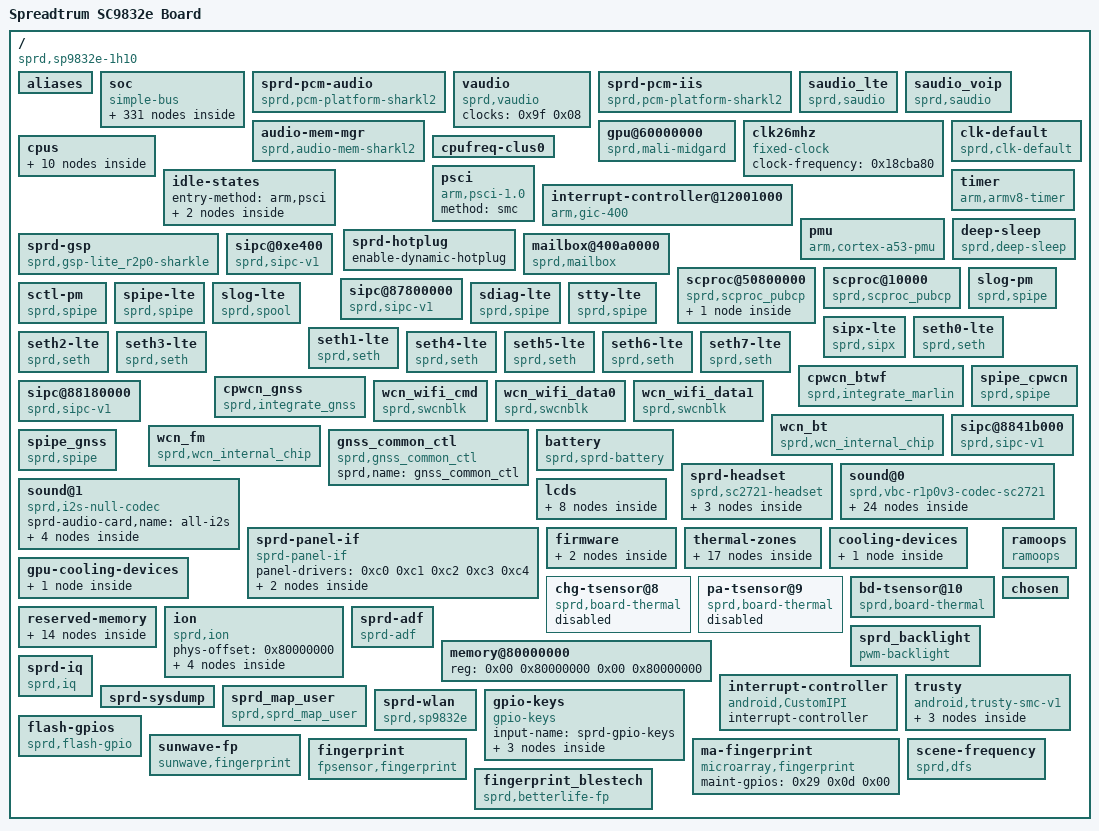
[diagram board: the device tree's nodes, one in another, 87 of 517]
/dts-v1/;

/ {
	interrupt-parent = <0x01>;
	#address-cells = <0x02>;
	#size-cells = <0x02>;
	cpuinfo_hardware = "Spreadtrum SC9832e";
	model = "Spreadtrum SC9832e Board";
	compatible = "sprd,sp9832e-1h10\0sprd,sc9832e";
	sprd,sc-id = <0x2668 0x01 0x20000>;

	aliases {
		serial1 = "/soc/ap-apb/serial@70100000";
		i2c0 = "/soc/ap-apb/i2c@70500000";
		i2c1 = "/soc/ap-apb/i2c@70600000";
		i2c2 = "/soc/ap-apb/i2c@70700000";
		i2c3 = "/soc/ap-apb/i2c@70800000";
		i2c4 = "/soc/ap-apb/i2c@70900000";
		spi0 = "/soc/ap-apb/spi@70a00000";
		spi1 = "/soc/ap-apb/spi@70b00000";
		spi2 = "/soc/ap-apb/spi@70c00000";
		hwspinlock1 = "/soc/aon/hwspinlock@33000000";
		thm-sensor0 = "/soc/aon/gpu-thm@402f0000";
		thm-sensor1 = "/soc/aon/cpu-thm@40300000";
		thm-sensor8 = "/chg-tsensor@8";
		thm-sensor9 = "/pa-tsensor@9";
		thm-sensor10 = "/bd-tsensor@10";
		thm-sensor11 = "/thermal-zones/cpu-thmzone";
		cooling-device0 = "/cooling-devices/cluster0-cooling";
		gpu-cooling0 = "/gpu-cooling-devices/gpu-cooling0";
	};

	soc {
		compatible = "simple-bus";
		#address-cells = <0x02>;
		#size-cells = <0x02>;
		ranges;

		syscon@20e00000 {
			compatible = "sprd,sys-ap-ahb\0syscon";
			reg = <0x00 0x20e00000 0x00 0x10000>;
			hwlocks = <0x02 0x01>;
			hwlock-names = "syscon";
			linux,phandle = <0x21>;
			phandle = <0x21>;
		};

		syscon@300e0000 {
			compatible = "sprd,sys-pub-apb\0syscon";
			reg = <0x00 0x300e0000 0x00 0x10000>;
			linux,phandle = <0xb2>;
			phandle = <0xb2>;
		};

		syscon@40200000 {
			compatible = "sprd,sys-aon-intc\0syscon";
			reg = <0x00 0x40200000 0x00 0x10000>;
			linux,phandle = <0xab>;
			phandle = <0xab>;
		};

		syscon@402b0000 {
			compatible = "sprd,sys-pmu-apb\0syscon";
			reg = <0x00 0x402b0000 0x00 0x10000>;
			#syscon-cells = <0x02>;
			hwlocks = <0x02 0x01>;
			hwlock-names = "syscon";
			linux,phandle = <0x3c>;
			phandle = <0x3c>;
		};

		syscon@402e0000 {
			compatible = "sprd,sys-aon-apb\0syscon";
			reg = <0x00 0x402e0000 0x00 0x10000>;
			hwlocks = <0x02 0x01>;
			hwlock-names = "syscon";
			linux,phandle = <0x2e>;
			phandle = <0x2e>;
		};

		syscon@403c0000 {
			compatible = "sprd,anlg_phy_g1\0syscon";
			reg = <0x00 0x403c0000 0x00 0x10000>;
			hwlocks = <0x02 0x01>;
			hwlock-names = "syscon";
		};

		syscon@403d0000 {
			compatible = "sprd,anlg_phy_g2\0syscon";
			reg = <0x00 0x403d0000 0x00 0x10000>;
			hwlocks = <0x02 0x01>;
			hwlock-names = "syscon";
		};

		syscon@403e0000 {
			compatible = "sprd,anlg_phy_top\0syscon";
			reg = <0x00 0x403e0000 0x00 0x10000>;
			hwlocks = <0x02 0x01>;
			hwlock-names = "syscon";
			linux,phandle = <0x2f>;
			phandle = <0x2f>;
		};

		syscon@403f0000 {
			compatible = "sprd,anlg_phy_g4\0syscon";
			reg = <0x00 0x403f0000 0x00 0x10000>;
			hwlocks = <0x02 0x01>;
			hwlock-names = "syscon";
		};

		syscon@40410000 {
			compatible = "sprd,anlg_phy_g6\0syscon";
			reg = <0x00 0x40410000 0x00 0x10000>;
			hwlocks = <0x02 0x01>;
			hwlock-names = "syscon";
			linux,phandle = <0x3b>;
			phandle = <0x3b>;
		};

		syscon@40420000 {
			compatible = "sprd,anlg_phy_g7\0syscon";
			reg = <0x00 0x40420000 0x00 0x10000>;
			hwlocks = <0x02 0x01>;
			hwlock-names = "syscon";
			linux,phandle = <0x4f>;
			phandle = <0x4f>;
		};

		syscon@40430000 {
			compatible = "sprd,anlg_phy_g8\0syscon";
			reg = <0x00 0x40430000 0x00 0x10000>;
			hwlocks = <0x02 0x01>;
			hwlock-names = "syscon";
		};

		syscon@40440000 {
			compatible = "sprd,anlg_wrap_wcn\0syscon";
			reg = <0x00 0x40440000 0x00 0x10000>;
			hwlocks = <0x02 0x01>;
			hwlock-names = "syscon";
			linux,phandle = <0xb3>;
			phandle = <0xb3>;
		};

		syscon@60d00000 {
			compatible = "sprd,sys-mm-ahb\0syscon";
			reg = <0x00 0x60d00000 0x00 0x10000>;
			hwlocks = <0x02 0x01>;
			hwlock-names = "syscon";
			linux,phandle = <0x4e>;
			phandle = <0x4e>;
		};

		syscon@71300000 {
			compatible = "sprd,sys-ap-apb\0syscon";
			reg = <0x00 0x71300000 0x00 0x40000>;
			hwlocks = <0x02 0x01>;
			hwlock-names = "syscon";
			linux,phandle = <0x20>;
			phandle = <0x20>;
		};

		syscon@71400000 {
			compatible = "sprd,sys-ap-intc\0syscon";
			reg = <0x00 0x71400000 0x00 0x10000>;
			linux,phandle = <0xa7>;
			phandle = <0xa7>;
		};

		syscon@71500000 {
			compatible = "sprd,sys-ap-intc\0syscon";
			reg = <0x00 0x71500000 0x00 0x10000>;
			linux,phandle = <0xa8>;
			phandle = <0xa8>;
		};

		syscon@71600000 {
			compatible = "sprd,sys-ap-intc\0syscon";
			reg = <0x00 0x71600000 0x00 0x10000>;
			linux,phandle = <0xa9>;
			phandle = <0xa9>;
		};

		syscon@71700000 {
			compatible = "sprd,sys-ap-intc\0syscon";
			reg = <0x00 0x71700000 0x00 0x10000>;
			linux,phandle = <0xaa>;
			phandle = <0xaa>;
		};

		ap-apb {
			compatible = "simple-bus";
			#address-cells = <0x02>;
			#size-cells = <0x02>;
			ranges;

			serial@70100000 {
				compatible = "sprd,sc9836-uart";
				reg = <0x00 0x70100000 0x00 0x100>;
				interrupts = <0x00 0x03 0x04>;
				clock-names = "enable\0uart\0source";
				clocks = <0x03 0x0e 0x04 0x05>;
				status = "okay";
			};

			i2c@70500000 {
				compatible = "sprd,r8p0-i2c";
				reg = <0x00 0x70500000 0x00 0x1000>;
				interrupts = <0x00 0x0b 0x04>;
				clock-names = "enable\0i2c\0source";
				clocks = <0x03 0x08 0x06 0x05>;
				clock-frequency = <0x61a80>;
				#address-cells = <0x01>;
				#size-cells = <0x00>;
				status = "okay";

				sensor-main@20 {
					compatible = "sprd,sensor-main";
					reg = <0x20>;
					clock-names = "clk_src\0sensor_eb\0clk_96m\0clk_76m8\0clk_48m\0clk_26m";
					clocks = <0x07 0x08 0x01 0x09 0x0a 0x0b 0x05>;
					vddio-supply = <0x0c>;
					vddcama-supply = <0x0d>;
					vddcamd-supply = <0x0e>;
					vddcammot-supply = <0x0f>;
					reset-gpios = <0x10 0x2c 0x00>;
					power-down-gpios = <0x10 0x2e 0x00>;
					host = "dcam0";

					port {

						endpoint {
							remote-endpoint = <0x11>;
							linux,phandle = <0x63>;
							phandle = <0x63>;
						};
					};
				};

				sensor-main2@6C {
					compatible = "sprd,sensor-main2";
					reg = <0x6c>;
					clock-names = "clk_src\0sensor_eb\0clk_96m\0clk_76m8\0clk_48m\0clk_26m";
					clocks = <0x12 0x08 0x02 0x09 0x0a 0x0b 0x05>;
					vddio-supply = <0x0c>;
					vddcama-supply = <0x0d>;
					vddcamd-supply = <0x0e>;
					vddcammot-supply = <0x0f>;
					reset-gpios = <0x10 0x2d 0x00>;
					power-down-gpios = <0x10 0x2f 0x00>;
					host = "dcam1";

					port {

						endpoint {
							remote-endpoint = <0x13>;
							linux,phandle = <0x65>;
							phandle = <0x65>;
						};
					};
				};
			};

			i2c@70600000 {
				compatible = "sprd,r8p0-i2c";
				reg = <0x00 0x70600000 0x00 0x1000>;
				interrupts = <0x00 0x0c 0x04>;
				clock-names = "enable\0i2c\0source";
				clocks = <0x03 0x09 0x14 0x05>;
				clock-frequency = <0x61a80>;
				#address-cells = <0x01>;
				#size-cells = <0x00>;
				status = "okay";

				sensor-sub@20 {
					compatible = "sprd,sensor-sub";
					reg = <0x20>;
					clock-names = "clk_src\0sensor_eb\0clk_96m\0clk_76m8\0clk_48m\0clk_26m";
					clocks = <0x12 0x08 0x02 0x09 0x0a 0x0b 0x05>;
					vddio-supply = <0x0c>;
					vddcama-supply = <0x0d>;
					vddcamd-supply = <0x0e>;
					vddcammot-supply = <0x0f>;
					reset-gpios = <0x10 0x29 0x00>;
					power-down-gpios = <0x10 0x28 0x00>;
					host = "dcam1";

					port {

						endpoint {
							remote-endpoint = <0x15>;
							linux,phandle = <0x66>;
							phandle = <0x66>;
						};
					};
				};
			};

			i2c@70700000 {
				compatible = "sprd,r8p0-i2c";
				reg = <0x00 0x70700000 0x00 0x1000>;
				interrupts = <0x00 0x0d 0x04>;
				clock-names = "enable\0i2c\0source";
				clocks = <0x03 0x0a 0x16 0x05>;
				clock-frequency = <0x61a80>;
				#address-cells = <0x01>;
				#size-cells = <0x00>;
				status = "okay";
			};

			i2c@70800000 {
				compatible = "sprd,r8p0-i2c";
				reg = <0x00 0x70800000 0x00 0x1000>;
				interrupts = <0x00 0x0e 0x04>;
				clock-names = "enable\0i2c\0source";
				clocks = <0x03 0x0b 0x17 0x05>;
				clock-frequency = <0x61a80>;
				#address-cells = <0x01>;
				#size-cells = <0x00>;
				status = "okay";

				tlsc6x@2e {
					compatible = "tlsc6x,tlsc6x_ts";
					reg = <0x2e>;
					gpios = <0x10 0x91 0x00 0x10 0x90 0x00>;
					vdd_name = "vdd18";
					TP_MAX_X = <480>;
					TP_MAX_Y = <960>;
				};
			};

			i2c@70900000 {
				compatible = "sprd,r8p0-i2c";
				reg = <0x00 0x70900000 0x00 0x1000>;
				interrupts = <0x00 0x0f 0x04>;
				clock-names = "enable\0i2c\0source";
				clocks = <0x03 0x0c 0x18 0x05>;
				clock-frequency = <0x61a80>;
				#address-cells = <0x01>;
				#size-cells = <0x00>;
				status = "okay";

				flash-ic@63 {
					compatible = "sprd,flash-ocp8137";
					reg = <0x63>;
					sprd,flash-ic = <0x1fc9>;
					sprd,torch = <0x01>;
					sprd,preflash = <0x01>;
					sprd,highlight = <0x01>;
					sprd,torch-level = <0x80>;
					sprd,preflash-level = <0x80>;
					sprd,highlight-level = <0x80>;
					sprd,lvfm-enable = <0x01>;
					flash-torch-en-gpios = <0x10 0x58 0x00>;
					flash-chip-en-gpios = <0x10 0x59 0x00>;
					flash-en-gpios = <0x10 0x4c 0x00>;
					flash-sync-gpios = <0x10 0x8d 0x00>;
				};

				charger@6a {
					compatible = "fairchild,fan54015_chg";
					reg = <0x6a>;
					chg-fault-gpios = <0x10 0x08 0x00>;
					vbus-det-gpios = <0x19 0x00 0x00>;
				};
			};

			spi@70a00000 {
				compatible = "sprd,spi-r4p0";
				reg = <0x00 0x70a00000 0x00 0x1000>;
				interrupts = <0x00 0x07 0x04>;
				clock-names = "enable\0spi\0source";
				sprd,dma-mode = <0x00>;
				sprd,rxtx-dma = <0x0b 0x0c>;
				dma-names = "rx_chn\0tx_chn";
				dmas = <0x1a 0x0b 0x1a 0x0c>;
				#address-cells = <0x01>;
				#size-cells = <0x00>;
				status = "okay";
				clocks = <0x03 0x05 0x1b 0x1c>;
			};

			spi@70b00000 {
				compatible = "sprd,spi-r4p0";
				reg = <0x00 0x70b00000 0x00 0x1000>;
				interrupts = <0x00 0x08 0x04>;
				clock-names = "enable\0spi\0source";
				sprd,dma-mode = <0x00>;
				sprd,rxtx-dma = <0x0d 0x0e>;
				dma-names = "rx_chn\0tx_chn";
				dmas = <0x1a 0x0d 0x1a 0x0e>;
				#address-cells = <0x01>;
				#size-cells = <0x00>;
				status = "disabled";
				clocks = <0x1d 0x09 0x1e 0x1c>;
			};

			spi@70c00000 {
				compatible = "sprd,spi-r4p0";
				reg = <0x00 0x70c00000 0x00 0x1000>;
				interrupts = <0x00 0x09 0x04>;
				clock-names = "enable\0spi\0source";
				sprd,dma-mode = <0x00>;
				sprd,rxtx-dma = <0x0f 0x10>;
				dma-names = "rx_chn\0tx_chn";
				dmas = <0x1a 0x0f 0x1a 0x10>;
				#address-cells = <0x01>;
				#size-cells = <0x00>;
				status = "disabled";
				clocks = <0x03 0x07 0x1f 0x1c>;
			};

			i2s@70d00000 {
				compatible = "sprd,i2s";
				reg = <0x00 0x70d00000 0x00 0x100000>;
				sprd,dai_name = "i2s_bt_sco0";
				sprd,hw_port = <0x00>;
				sprd,syscon-ap-apb = <0x20>;
				#sound-dai-cells = <0x00>;
				status = "okay";
				sprd,config_type = "pcm";
				sprd,slave_timeout = <0xf11>;
				sprd,_hw_port = <0x00>;
				sprd,fs = <0x1f40>;
				sprd,bus_type = <0x01>;
				sprd,rtx_mode = <0x03>;
				sprd,byte_per_chan = <0x01>;
				sprd,slave_mode = <0x00>;
				sprd,lsb = <0x00>;
				sprd,lrck = <0x00>;
				sprd,low_for_left = <0x01>;
				sprd,clk_inv = <0x00>;
				sprd,pcm_short_frame = <0x01>;
				sprd,pcm_slot = <0x01>;
				sprd,pcm_cycle = <0x01>;
				sprd,tx_watermark = <0x0c>;
				sprd,rx_watermark = <0x14>;
				linux,phandle = <0xbf>;
				phandle = <0xbf>;
			};
		};

		ap-ahb {
			compatible = "simple-bus";
			#address-cells = <0x02>;
			#size-cells = <0x02>;
			ranges;

			dma-controller@20100000 {
				compatible = "sprd,ap-dma-v4.0";
				reg = <0x00 0x20100000 0x00 0x4000>;
				interrupts = <0x00 0x32 0x04>;
				#dma-cells = <0x01>;
				#dma-channels = <0x1c>;
				sprd,full-type-offset = <0x00>;
				sprd,syscon-dma-glb = <0x21>;
				clock-names = "enable";
				clocks = <0x22 0x05>;
				linux,phandle = <0x1a>;
				phandle = <0x1a>;
			};

			sdio@20600000 {
				compatible = "sprd,sdhc-r10";
				reg = <0x00 0x20600000 0x00 0x1000>;
				interrupts = <0x00 0x3c 0x04>;
				status = "okay";
				clock-names = "sdio_clk\0sdio_clk_source\0sdio_ahb_enable";
				clocks = <0x23 0x24 0x22 0x0b>;
				sprd,hs400es-dly = <0x5a 0x7f 0x30 0x30>;
				sprd,hs400-dly = <0x5a 0x8c 0x30 0x30>;
				sprd,hs200-dly = <0x7f 0x8c 0x8e 0x8e>;
				sprd,ddr52-dly = <0x9f 0xb3 0x1e 0x1e>;
				vmmc-supply = <0x25>;
				voltage-ranges = <0xbb8 0xbb8>;
				bus-width = <0x08>;
				non-removable;
				cap-mmc-hw-reset;
				mmc-hs400-enhanced-strobe;
				mmc-hs400-1_8v;
				mmc-hs200-1_8v;
				mmc-ddr-1_8v;
				sprd,name = "sdio_emmc";
				sprd,sdio-adma;
				no-sdio;
				no-sd;
			};

			sdio@20300000 {
				compatible = "sprd,sdhc-r10";
				reg = <0x00 0x20300000 0x00 0x1000>;
				interrupts = <0x00 0x39 0x04>;
				status = "okay";
				clock-names = "sdio_clk\0sdio_clk_source\0sdio_ahb_enable";
				clocks = <0x26 0x24 0x22 0x08>;
				sprd,sdr104-dly = <0x7f 0x94 0xa7 0xa7>;
				sprd,sdr50-dly = <0x7f 0x4a 0x4a 0x4a>;
				vmmc-supply = <0x27>;
				vqmmc-supply = <0x28>;
				voltage-ranges = <0xbb8 0xbb8>;
				bus-width = <0x04>;
				sd-uhs-sdr50;
				sd-uhs-sdr104;
				cd-gpios = <0x29 0x09 0x00>;
				sprd,name = "sdio_sd";
				sprd,sdio-adma;
				no-sdio;
				no-mmc;
			};

			usb@20200000 {
				compatible = "sprd,usb";
				reg = <0x00 0x20200000 0x00 0x2000>;
				interrupts = <0x00 0x37 0x04>;
				interrupt-names = "mc";
				clocks = <0x22 0x04>;
				clock-names = "core_clk";
				phy-type = "usb20_sprd_phy";
				usb-phy = <0x2a>;
				phy-names = "usb";
				dr-mode = "peripheral";
				sprd,cable-detection-method = "typec";
				sprd,vbus-gpios = <0x19 0x00 0x00>;
			};

			iommu@20800160 {
				compatible = "sprd,iommuexle-dispc";
				reg = <0x00 0x20800160 0x00 0x04 0x00 0x20800800 0x00 0x60 0x00 0x70000000 0x00 0x8000000>;
				reg_name = "mmu_interrupt_reg\0mmu_reg\0iova pool";
				status = "okay";
				#iommu-cells = <0x00>;
				linux,phandle = <0x34>;
				phandle = <0x34>;
			};

			iommu@20a00800 {
				compatible = "sprd,iommuexle-gsp";
				reg = <0x00 0x20a00800 0x00 0x04 0x00 0x20a00804 0x00 0x60 0x00 0x20000000 0x00 0x10000000>;
				reg_name = "mmu_interrupt_reg\0mmu_reg\0iova pool";
				status = "okay";
				#iommu-cells = <0x00>;
				linux,phandle = <0x2b>;
				phandle = <0x2b>;
			};

			gsp@20a00000 {
				compatible = "sprd,gsp-core";
				reg = <0x00 0x20a00000 0x00 0x1000>;
				core-id = <0x00>;
				kcfg-num = <0x08>;
				interrupts = <0x00 0x33 0x04>;
				iommus = <0x2b>;
				sprd,sys-ap-ahb = <0x21>;
				clock-names = "clk_gsp\0clk_gsp_parent\0clk_gsp_eb";
				clocks = <0x2c 0x2d 0x22 0x03>;
				linux,phandle = <0xa6>;
				phandle = <0xa6>;
			};

			hsphy@20e00000 {
				compatible = "sprd,usb-phy";
				reg = <0x00 0x20e00000 0x00 0x3030>;
				reg-names = "phy_glb_regs";
				sprd,syscon-enable = <0x2e>;
				sprd,syscon-usb2iso = <0x2f>;
				sprd,tune-value = <0x5af33>;
				sprd,vdd-voltage = <0x325aa0>;
				#phy-cells = <0x00>;
				vdd-supply = <0x30>;
				linux,phandle = <0x2a>;
				phandle = <0x2a>;
			};

			dispc@20800000 {
				compatible = "sprd,display-controller";
				reg = <0x00 0x20800000 0x00 0x1000>;
				dev-id = <0x00>;
				sprd,dpi_clk_div = <0x01>;
				interrupts = <0x00 0x2e 0x04>;
				clock-src = <0x16e36000 0x7a12000>;
				clock-names = "clk_dispc_core_parent\0clk_dispc_dpi_parent\0clk_dispc_core\0clk_dispc_dpi\0clk_dispc_ahb_eb";
				clocks = <0x2d 0x31 0x32 0x33 0x22 0x01>;
				iommus = <0x34>;
				status = "okay";
				sprd,ip = "dpu-lite-r1p0";
				sprd,soc = "sharkle";
				linux,phandle = <0xd3>;
				phandle = <0xd3>;

				port {

					endpoint@0 {
						remote-endpoint = <0x35>;
						linux,phandle = <0x37>;
						phandle = <0x37>;
					};
				};
			};

			dsi@21800000 {
				compatible = "sprd,dsi-controller";
				#address-cells = <0x01>;
				#size-cells = <0x00>;
				dev-id = <0x00>;
				reg = <0x00 0x21800000 0x00 0x1000>;
				interrupts = <0x00 0x30 0x04 0x00 0x31 0x04>;
				clock-names = "clk_dsi0_ahb_eb";
				clocks = <0x22 0x00>;
				status = "okay";
				sprd,ip = "sprd,dsi-ctrl-r1p0";
				sprd,soc = "sharkle";

				port@0 {
					reg = <0x00>;

					endpoint {
						remote-endpoint = <0x36>;
						linux,phandle = <0x39>;
						phandle = <0x39>;
					};
				};

				port@1 {
					reg = <0x01>;

					endpoint {
						remote-endpoint = <0x37>;
						linux,phandle = <0x35>;
						phandle = <0x35>;
					};
				};
			};

			dphy@0 {
				compatible = "sprd,mipi-dsi-phy";
				#address-cells = <0x01>;
				#size-cells = <0x00>;
				reg = <0x00 0x21800000 0x00 0x1000>;
				status = "okay";
				sprd,ip = "sprd,megacores-sharkle";
				sprd,soc = "sharkle";

				port@0 {
					reg = <0x00>;

					endpoint {
						remote-endpoint = <0x38>;
						linux,phandle = <0xc5>;
						phandle = <0xc5>;
					};
				};

				port@1 {
					reg = <0x01>;

					endpoint {
						remote-endpoint = <0x39>;
						linux,phandle = <0x36>;
						phandle = <0x36>;
					};
				};
			};

			lcds {

				lcdffff@0 {
					work-mode = <0x01>;
					bpp = <0x18>;
					lane-number = <0x04>;
					fps = <0x3c>;
					panel-name = "lcd_dummy_mipi_hd";
					power-on-sequence = <0x32 0x01 0x14 0x32 0x00 0x14 0x32 0x01 0x78>;
					power-off-sequence = <0x32 0x00 0x14>;
					init-data = <0x15780002 0x11001500 0x22900>;
					sleep-in = <0x15000002 0x28001578 0x21000>;
					sleep-out = <0x15780002 0x11001500 0x22900>;
					linux,phandle = <0xc4>;
					phandle = <0xc4>;

					display-timings {
						clock-frequency = <0x7a120>;
						hactive = <0x2d0>;
						vactive = <0x500>;
						hback-porch = <0x30>;
						hfront-porch = <0x30>;
						vback-porch = <0x10>;
						vfront-porch = <0x10>;
						hsync-len = <0x08>;
						vsync-len = <0x08>;
					};
				};
			};
		};

		aon {
			compatible = "simple-bus";
			#address-cells = <0x02>;
			#size-cells = <0x02>;
			ranges;

			hwspinlock@33000000 {
				compatible = "sprd,hwspinlock-r3p0";
				reg = <0x00 0x33000000 0x00 0x1000>;
				#hwlock-cells = <0x01>;
				hwlocks-base = <0x00>;
				hwlocks-num = <0x20>;
				clock-names = "enable";
				clocks = <0x3a 0x16>;
				linux,phandle = <0x02>;
				phandle = <0x02>;
			};

			audio-codec@40000000 {
				compatible = "sprd,sharkl2-audio-codec";
				reg = <0x00 0x40000000 0x00 0x2000>;
				interrupts = <0x00 0x14 0x00>;
				sprd,syscon-aon-apb = <0x2e>;
				sprd,anlg-phy-g-syscon = <0x3b>;
				linux,phandle = <0x4d>;
				phandle = <0x4d>;
			};

			vbc@40020000 {
				compatible = "sprd,vbc-r1p0v3";
				#sound-dai-cells = <0x01>;
				reg = <0x00 0x40020000 0x00 0x10000>;
				sprd,clk-stable = <0x402d0060 0x04>;
				sprd,syscon-aon-apb = <0x2e>;
				sprd,syscon-pmu-apb = <0x3c>;
				sprd,dynamic-eq-support = <0x00>;
				sprd,vbc-iis-lr-invert = <0x00 0x01 0x01>;
				sprd,vbc-use-dma-type = <0x00 0x00 0x01 0x01>;
				sprd,vbc-use-ad01-only = <0x01>;
				pinctrl-names = "vbc_iis1_0\0ap_iis0_0\0tgdsp_iis0_0\0tgdsp_iis1_0\0pubcp_iis0_0\0ap_iis0_1\0tgdsp_iis0_1\0tgdsp_iis1_1\0pubcp_iis0_1\0vbc_iis2_1\0vbc_iis3_1";
				pinctrl-0 = <0x3d>;
				pinctrl-1 = <0x3e>;
				pinctrl-2 = <0x3f>;
				pinctrl-3 = <0x40>;
				pinctrl-4 = <0x41>;
				pinctrl-5 = <0x42>;
				pinctrl-6 = <0x43>;
				pinctrl-7 = <0x44>;
				pinctrl-8 = <0x45>;
				pinctrl-9 = <0x46>;
				pinctrl-10 = <0x47>;
				linux,phandle = <0xbb>;
				phandle = <0xbb>;
			};

			timer@40050000 {
				compatible = "sprd,bcevt-r4p0";
				reg = <0x00 0x40050000 0x00 0x14>;
				interrupts = <0x00 0x1c 0x04>;
				clock-frequency = <0x8000>;
			};

			dma-controller@40100000 {
				compatible = "sprd,aon-dma-v2.0";
				reg = <0x00 0x40100000 0x00 0x4000>;
				#dma-cells = <0x01>;
				#dma-channels = <0x08>;
				sprd,full-type-offset = <0x00>;
				sprd,syscon-dma-glb = <0x2e>;
				clock-names = "enable";
				clocks = <0x48 0x16>;
				linux,phandle = <0x9d>;
				phandle = <0x9d>;
			};

			gpio-controller@40210000 {
				compatible = "sprd,ap-eic";
				reg = <0x00 0x40210000 0x00 0x80 0x00 0x40370000 0x00 0x80 0x00 0x402c0000 0x00 0x80>;
				gpio-controller;
				#gpio-cells = <0x02>;
				sprd,gpiobase = <0x120>;
				sprd,ngpios = <0x20>;
				interrupt-controller;
				#interrupt-cells = <0x02>;
				interrupts = <0x00 0x25 0x04>;
				linux,phandle = <0xda>;
				phandle = <0xda>;
			};

			gpio-controller@402100a0 {
				compatible = "sprd,ap-eic-async";
				reg = <0x00 0x402100a0 0x00 0x40 0x00 0x403700a0 0x00 0x40 0x00 0x402c00a0 0x00 0x40>;
				gpio-controller;
				#gpio-cells = <0x02>;
				sprd,gpiobase = <0x150>;
				sprd,ngpios = <0x20>;
				interrupt-controller;
				#interrupt-cells = <0x02>;
				interrupts = <0x00 0x25 0x04>;
				linux,phandle = <0x29>;
				phandle = <0x29>;
			};

			efuse@40240000 {
				compatible = "sprd,ap_r6p0_efuse";
				sprd,syscon-enable = <0x2e>;
				reg = <0x00 0x40240000 0x00 0x10000>;
				clock-names = "enable";
				clocks = <0x3a 0x0d>;
				sprd,uid-start = <0x5e 0x00>;
				sprd,uid-end = <0x5f 0x00>;
				sprd,block-start = <0x24>;
				sprd,block-num = <0x0a>;
				sprd,block-width = <0x20>;
				hwlocks = <0x02 0x08>;
				hwlock-names = "ap_efuse";
			};

			gpio-controller@40280000 {
				compatible = "sprd,ap-gpio";
				reg = <0x00 0x40280000 0x00 0x1000>;
				gpio-controller;
				#gpio-cells = <0x02>;
				sprd,gpiobase = <0x00>;
				sprd,ngpios = <0x100>;
				interrupt-controller;
				#interrupt-cells = <0x02>;
				interrupts = <0x00 0x23 0x04>;
				linux,phandle = <0x10>;
				phandle = <0x10>;
			};

			pinctrl@402a0000 {
				compatible = "sprd,sc9832e-pinctrl";
				reg = <0x00 0x402a0000 0x00 0x10000>;

				reg2-iis0-0 {
					pins = <0x1c11032 0x00>;
					linux,phandle = <0x3d>;
					phandle = <0x3d>;
				};

				reg2-iis0-1 {
					pins = <0x1c11032 0x01>;
					linux,phandle = <0x3e>;
					phandle = <0x3e>;
				};

				reg3-iis0-2 {
					pins = <0x1c11032 0x02>;
					linux,phandle = <0x3f>;
					phandle = <0x3f>;
				};

				reg2-iis0-3 {
					pins = <0x1c11032 0x03>;
					linux,phandle = <0x40>;
					phandle = <0x40>;
				};

				reg2-iis0-4 {
					pins = <0x1c11032 0x04>;
					linux,phandle = <0x41>;
					phandle = <0x41>;
				};

				reg3-iis1-0 {
					pins = <0x2710a33 0x00>;
					linux,phandle = <0x42>;
					phandle = <0x42>;
				};

				reg3-iis1-1 {
					pins = <0x2710a33 0x02>;
					linux,phandle = <0x43>;
					phandle = <0x43>;
				};

				reg3-iis1-2 {
					pins = <0x2710a33 0x03>;
					linux,phandle = <0x44>;
					phandle = <0x44>;
				};

				reg3-iis1-3 {
					pins = <0x2710a33 0x01>;
					linux,phandle = <0x45>;
					phandle = <0x45>;
				};

				reg3-iis1-4 {
					pins = <0x2710a33 0x04>;
					linux,phandle = <0x46>;
					phandle = <0x46>;
				};

				reg3-iis1-5 {
					pins = <0x2710a33 0x05>;
					linux,phandle = <0x47>;
					phandle = <0x47>;
				};
			};

			gpu-thm@402f0000 {
				compatible = "sprd,r2p0-thm";
				sprd,syscon-enable = <0x2e>;
				reg = <0x00 0x402f0000 0x00 0x100>;
				clock-names = "enable";
				clocks = <0x48 0x01>;
				#thermal-sensor-cells = <0x01>;
				power-down = <0x00>;
				otp-temp = <0x1d4c0>;
				algor_ver = <0x01>;
				cal_k = <0x387>;
				cal_b = <0x1167a>;
				cal_efuse_blk = <0x2c>;
				cal_efuse_bit = <0x09>;
				ratio_off_bit = <0x02>;
				ratio_sign_bit = <0x01>;
				linux,phandle = <0xc9>;
				phandle = <0xc9>;
			};

			cpu-thm@40300000 {
				compatible = "sprd,r2p0-thm";
				sprd,syscon-enable = <0x2e>;
				reg = <0x00 0x40300000 0x00 0x100>;
				clock-names = "enable";
				clocks = <0x48 0x13>;
				#thermal-sensor-cells = <0x01>;
				power-down = <0x00>;
				otp-temp = <0x1d4c0>;
				algor_ver = <0x01>;
				cal_k = <0x387>;
				cal_b = <0x1167a>;
				cal_efuse_blk = <0x2c>;
				cal_efuse_bit = <0x18>;
				ratio_off_bit = <0x11>;
				ratio_sign_bit = <0x10>;
				linux,phandle = <0xc6>;
				phandle = <0xc6>;
			};

			pwm@40260020 {
				#pwm-cells = <0x02>;
				compatible = "sprd,pwm-r3p0";
				reg = <0x00 0x40260020 0x00 0x10000>;
				status = "okay";
				clock-names = "sprd_pwm_clk_parent\0clk_pwm";
				clocks = <0x05 0x49>;
				linux,phandle = <0xd4>;
				phandle = <0xd4>;
			};

			watchdog@40310000 {
				compatible = "sprd,sharkl2-wdt";
				reg = <0x00 0x40310000 0x00 0x1000>;
				interrupts = <0x00 0x7c 0x04>;
				clock-names = "enable\0rtc_enable";
				sprd,wdt-enable = <0x2e>;
				sprd,wdt-phandle = <0x4a>;
				clocks = <0x48 0x08 0x4b 0x09>;
			};

			spi@40380000 {
				compatible = "sprd,r3p0-adi";
				reg = <0x00 0x40380000 0x00 0x10000>;
				#address-cells = <0x01>;
				#size-cells = <0x00>;
				sprd,hw-channels = <0x1e 0x8c20>;

				pmic@0 {
					compatible = "sprd,sc2721";
					reg = <0x00>;
					spi-max-frequency = <0x18cba80>;
					#address-cells = <0x01>;
					#size-cells = <0x00>;
					interrupt-controller;
					#interrupt-cells = <0x02>;
					interrupts = <0x00 0x26 0x04>;
					sprd,pmic_intc_base = <0xc0>;
					sprd,pmic_intc_irqmax = <0x10>;
					linux,phandle = <0x4c>;
					phandle = <0x4c>;

					timer@00 {
						compatible = "sprd,sc2721-chg-timer";
						reg = <0x00>;
						interrupt-parent = <0x4c>;
						interrupts = <0x07 0x04>;
					};

					watchdog@40 {
						compatible = "sprd,sc2721-wdt";
						reg = <0x40>;
						linux,phandle = <0x4a>;
						phandle = <0x4a>;
					};

					watchdog@80 {
						compatible = "sprd,sc2721-chg-wdt";
						reg = <0x80>;
						status = "disabled";
					};

					bltc-rgb@180 {
						compatible = "sprd,sc2721-bltc-rgb";
						reg = <0x180>;
						status = "okay";
					};

					rtc@200 {
						compatible = "sprd,sc2721-rtc";
						interrupt-parent = <0x4c>;
						interrupts = <0x01 0x04>;
						reg = <0x200>;
					};

					gpio-controller@280 {
						compatible = "sprd,sc2721-eic";
						reg = <0x280>;
						interrupts = <0x04 0x04>;
						interrupt-parent = <0x4c>;
						gpio-controller;
						#gpio-cells = <0x02>;
						sprd,gpiobase = <0x140>;
						sprd,ngpios = <0x10>;
						interrupt-controller;
						#interrupt-cells = <0x02>;
						linux,phandle = <0x19>;
						phandle = <0x19>;
					};

					kpled@2ac {
						compatible = "sprd,sc2721-kpled";
						brightness_max = <0xff>;
						brightness_min = <0x00>;
						run_mode = <0x01>;
						reg = <0x2ac 0x2b0>;
						status = "disabled";
					};

					flash-kpled {
						compatible = "sprd,flash-kpled";
					};

					flash-sink {
						compatible = "sprd,flash-sink";
					};

					efuse@300 {
						compatible = "sprd,sc2721-efuse";
						reg = <0x300>;
						sprd,block-num = <0x20>;
						sprd,block-width = <0x10>;
						hwlocks = <0x02 0x0c>;
						hwlock-names = "pmic_efuse";
					};

					typec@380 {
						compatible = "sprd,typec";
						interrupt-parent = <0x4c>;
						interrupts = <0x0a 0x04>;
						reg = <0x380>;
						mode = <0x02>;
						tsleep = <0x00>;
						ext-ldo-sw = <0x00>;
						status = "okay";
					};

					adc@400 {
						compatible = "sprd,sc2721-adc";
						reg = <0x400>;
						#io-channel-cells = <0x01>;
						hwlocks = <0x02 0x04>;
						hwlock-names = "pmic_adc";
						linux,phandle = <0xb8>;
						phandle = <0xb8>;
					};

					audio-codec@700 {
						compatible = "sprd,sc2721-audio-codec";
						#sound-dai-cells = <0x01>;
						reg = <0x700>;
						interrupts = <0x06 0x00>;
						sprd,syscon-pmu-apb = <0x3c>;
						status = "okay";
						digital-codec = <0x4d>;
						linux,phandle = <0xbc>;
						phandle = <0xbc>;
					};

					power-controller@810 {
						compatible = "sprd,sc2721-regulator";
						reg = <0xc28 0xcd4 0xd00 0xd1c 0xd20 0xd3c>;

						regulators {
							#address-cells = <0x01>;
							#size-cells = <0x00>;

							dcdc@0 {
								reg = <0x00>;
								regulator-name = "vddcpu";
								sprd,default-microvolt = <0xdbba0>;
								sprd,step-microvolt = <0xc35>;
								regulator-min-microvolt = <0x61a80>;
								regulator-max-microvolt = <0x1e74e0>;
								regulator-microvolt-offset = <0x00>;
								sprd,hide-offset = <0x3e8>;
								sprd,default-on;
								linux,phandle = <0xa4>;
								phandle = <0xa4>;
							};

							dcdc@1 {
								reg = <0x01>;
								regulator-name = "vddcore";
								sprd,default-microvolt = <0xdbba0>;
								sprd,step-microvolt = <0xc35>;
								regulator-min-microvolt = <0x61a80>;
								regulator-max-microvolt = <0x1e74e0>;
								regulator-microvolt-offset = <0x00>;
								sprd,hide-offset = <0x3e8>;
								sprd,default-on;
								linux,phandle = <0xa0>;
								phandle = <0xa0>;
							};

							dcdc@2 {
								reg = <0x02>;
								regulator-name = "vddmem";
								sprd,default-microvolt = <0x155cc0>;
								sprd,step-microvolt = <0xc35>;
								regulator-min-microvolt = <0x61a80>;
								regulator-max-microvolt = <0x1e74e0>;
								regulator-microvolt-offset = <0x00>;
								sprd,hide-offset = <0x3e8>;
								sprd,default-on;
							};

							dcdc@3 {
								reg = <0x03>;
								regulator-name = "vddgen";
								sprd,default-microvolt = <0x1c3a90>;
								sprd,step-microvolt = <0xc35>;
								regulator-min-microvolt = <0x927c0>;
								regulator-max-microvolt = <0x387520>;
								regulator-microvolt-offset = <0x00>;
								sprd,hide-offset = <0x3e8>;
								sprd,default-on;
							};

							dcdc@4 {
								reg = <0x04>;
								regulator-name = "vddwpa";
								sprd,default-microvolt = <0xf4240>;
								sprd,step-microvolt = <0xc35>;
								regulator-min-microvolt = <0x927c0>;
								regulator-max-microvolt = <0x36dee0>;
								regulator-microvolt-offset = <0x00>;
								sprd,hide-offset = <0x3e8>;
							};

							ldo@5 {
								reg = <0x05>;
								regulator-name = "vddcama";
								sprd,default-microvolt = <0x2ab980>;
								sprd,step-microvolt = <0x2710>;
								regulator-min-microvolt = <0x124f80>;
								regulator-max-microvolt = <0x393870>;
								regulator-microvolt-offset = <0x00>;
								sprd,hide-offset = <0x3e8>;
								linux,phandle = <0x0d>;
								phandle = <0x0d>;
							};

							ldo@6 {
								reg = <0x06>;
								regulator-name = "vddcammot";
								sprd,default-microvolt = <0x2ab980>;
								sprd,step-microvolt = <0x2710>;
								regulator-min-microvolt = <0x124f80>;
								regulator-max-microvolt = <0x393870>;
								regulator-microvolt-offset = <0x00>;
								sprd,hide-offset = <0x3e8>;
								linux,phandle = <0x0f>;
								phandle = <0x0f>;
							};

							ldo@7 {
								reg = <0x07>;
								regulator-name = "vddsim0";
								sprd,default-microvolt = <0x1b7740>;
								sprd,step-microvolt = <0x2710>;
								regulator-min-microvolt = <0x124f80>;
								regulator-max-microvolt = <0x23c3460>;
								regulator-microvolt-offset = <0x00>;
								sprd,hide-offset = <0x3e8>;
								status = "disabled";
							};

							ldo@8 {
								reg = <0x08>;
								regulator-name = "vddsim1";
								sprd,default-microvolt = <0x1b7740>;
								sprd,step-microvolt = <0x2710>;
								regulator-min-microvolt = <0x124f80>;
								regulator-max-microvolt = <0x393870>;
								regulator-microvolt-offset = <0x00>;
								sprd,hide-offset = <0x3e8>;
								status = "disabled";
							};

							ldo@9 {
								reg = <0x09>;
								regulator-name = "vddsim2";
								sprd,default-microvolt = <0x1b7740>;
								sprd,step-microvolt = <0x2710>;
								regulator-min-microvolt = <0x124f80>;
								regulator-max-microvolt = <0x393870>;
								regulator-microvolt-offset = <0x00>;
								sprd,hide-offset = <0x3e8>;
							};

							ldo@10 {
								reg = <0x0a>;
								regulator-name = "vddemmccore";
								sprd,default-microvolt = <0x2dc6c0>;
								sprd,step-microvolt = <0x2710>;
								regulator-min-microvolt = <0x124f80>;
								regulator-max-microvolt = <0x393870>;
								regulator-microvolt-offset = <0x00>;
								sprd,default-on;
								sprd,hide-offset = <0x3e8>;
								linux,phandle = <0x25>;
								phandle = <0x25>;
							};

							ldo@11 {
								reg = <0x0b>;
								regulator-name = "vddsdcore";
								sprd,default-microvolt = <0x2dc6c0>;
								sprd,step-microvolt = <0x2710>;
								regulator-min-microvolt = <0x124f80>;
								regulator-max-microvolt = <0x393870>;
								regulator-microvolt-offset = <0x00>;
								sprd,default-on;
								sprd,hide-offset = <0x3e8>;
								regulator-always-on;
								linux,phandle = <0x27>;
								phandle = <0x27>;
							};

							ldo@12 {
								reg = <0x0c>;
								regulator-name = "vddsdio";
								sprd,default-microvolt = <0x2dc6c0>;
								sprd,step-microvolt = <0x2710>;
								regulator-min-microvolt = <0x124f80>;
								regulator-max-microvolt = <0x393870>;
								regulator-microvolt-offset = <0x00>;
								sprd,default-on;
								sprd,hide-offset = <0x3e8>;
								linux,phandle = <0x28>;
								phandle = <0x28>;
							};

							ldo@13 {
								reg = <0x0d>;
								regulator-name = "vdd28";
								sprd,default-microvolt = <0x2ab980>;
								sprd,step-microvolt = <0x2710>;
								regulator-min-microvolt = <0x124f80>;
								regulator-max-microvolt = <0x393870>;
								regulator-microvolt-offset = <0x00>;
								sprd,default-on;
								sprd,hide-offset = <0x3e8>;
							};

							ldo@14 {
								reg = <0x0e>;
								regulator-name = "vddwifipa";
								sprd,default-microvolt = <0x325aa0>;
								sprd,step-microvolt = <0x2710>;
								regulator-min-microvolt = <0x124f80>;
								regulator-max-microvolt = <0x393870>;
								regulator-microvolt-offset = <0x00>;
								sprd,hide-offset = <0x3e8>;
								linux,phandle = <0xb6>;
								phandle = <0xb6>;
							};

							ldo@15 {
								reg = <0x0f>;
								regulator-name = "vdddcxo";
								sprd,default-microvolt = <0x1b7740>;
								sprd,step-microvolt = <0x2710>;
								regulator-min-microvolt = <0x124f80>;
								regulator-max-microvolt = <0x393870>;
								regulator-microvolt-offset = <0x00>;
								sprd,default-on;
								sprd,hide-offset = <0x3e8>;
							};

							ldo@16 {
								reg = <0x10>;
								regulator-name = "vddusb33";
								sprd,default-microvolt = <0x325aa0>;
								sprd,step-microvolt = <0x2710>;
								regulator-min-microvolt = <0x124f80>;
								regulator-max-microvolt = <0x393870>;
								regulator-microvolt-offset = <0x00>;
								sprd,default-on;
								sprd,hide-offset = <0x3e8>;
								linux,phandle = <0x30>;
								phandle = <0x30>;
							};

							ldo@17 {
								reg = <0x11>;
								regulator-name = "vddcamd";
								sprd,default-microvolt = <0x10c8e0>;
								sprd,step-microvolt = <0x186a>;
								regulator-min-microvolt = <0xf4240>;
								regulator-max-microvolt = <0x16e360>;
								regulator-microvolt-offset = <0x00>;
								sprd,hide-offset = <0x3e8>;
								linux,phandle = <0x0e>;
								phandle = <0x0e>;
							};

							ldo@18 {
								reg = <0x12>;
								regulator-name = "vddcon";
								sprd,default-microvolt = <0x186a00>;
								sprd,step-microvolt = <0x186a>;
								regulator-min-microvolt = <0x10c8e0>;
								regulator-max-microvolt = <0x186a00>;
								regulator-microvolt-offset = <0x00>;
								sprd,hide-offset = <0x3e8>;
								linux,phandle = <0xb5>;
								phandle = <0xb5>;
							};

							ldo@19 {
								reg = <0x13>;
								regulator-name = "vddcamio";
								sprd,default-microvolt = <0x1b7740>;
								sprd,step-microvolt = <0x186a>;
								regulator-min-microvolt = <0x10c8e0>;
								regulator-max-microvolt = <0x1cfde0>;
								regulator-microvolt-offset = <0x00>;
								sprd,hide-offset = <0x3e8>;
								sprd,default-on;
								linux,phandle = <0x0c>;
								phandle = <0x0c>;
							};

							ldo@20 {
								reg = <0x14>;
								regulator-name = "vdd18";
								sprd,default-microvolt = <0x1b7740>;
								sprd,step-microvolt = <0x186a>;
								regulator-min-microvolt = <0x10c8e0>;
								regulator-max-microvolt = <0x1cfde0>;
								regulator-microvolt-offset = <0x00>;
								sprd,hide-offset = <0x3e8>;
								sprd,default-on;
							};

							ldo@21 {
								reg = <0x15>;
								regulator-name = "vddrf18";
								sprd,default-microvolt = <0x1b7740>;
								sprd,step-microvolt = <0x186a>;
								regulator-min-microvolt = <0x10c8e0>;
								regulator-max-microvolt = <0x1cfde0>;
								regulator-microvolt-offset = <0x00>;
								sprd,default-on;
								sprd,hide-offset = <0x3e8>;
							};

							ldo@22 {
								reg = <0x16>;
								regulator-name = "vddrf15";
								sprd,default-microvolt = <0x1312d0>;
								sprd,step-microvolt = <0x186a>;
								regulator-min-microvolt = <0x10c8e0>;
								regulator-max-microvolt = <0x155cc0>;
								regulator-microvolt-offset = <0x00>;
								sprd,hide-offset = <0x3e8>;
							};

							ldo@23 {
								reg = <0x17>;
								regulator-name = "vddldomem";
								sprd,default-microvolt = <0x1312d0>;
								sprd,step-microvolt = <0x186a>;
								regulator-min-microvolt = <0x10c8e0>;
								regulator-max-microvolt = <0x155cc0>;
								regulator-microvolt-offset = <0x00>;
								sprd,hide-offset = <0x3e8>;
								sprd,default-on;
							};
						};
					};

					fast-charger@900 {
						compatible = "sprd,sc2721-fchg";
						reg = <0x900>;
						interrupt-parent = <0x4c>;
						interrupts = <0x05 0x04>;
						status = "disabled";
					};

					fgu@a00 {
						compatible = "sprd,sc2721-fgu";
						reg = <0xa00>;
						interrupt-parent = <0x4c>;
						interrupts = <0x03 0x04>;
						ocv-type = <0x01>;
					};

					global@c00 {
						compatible = "sprd,pmic-glb";
						reg = <0xc00>;
					};

					vibrator@eb4 {
						compatible = "sprd,sc2721-vibrator";
						reg = <0xeb4>;
					};

					charger@ec0 {
						compatible = "sprd,sc2721-charger";
						reg = <0xec0>;
						chg-cv-gpios = <0x19 0x04 0x00>;
						chg-ovi-gpios = <0x19 0x06 0x00>;
						status = "okay";
					};

					power@efc {
						compatible = "sprd,sc2721-poweroff";
						reg = <0xefc>;
					};

					reset@f1c {
						compatible = "sprd,sc2721-7sreset";
						reg = <0xf1c 0xeec>;
					};
				};
			};

			aon-bm@40340000 {
				compatible = "sprd,aon-bm-r5p3";
				reg = <0x00 0x40340000 0x00 0x10000>;
				interrupts = <0x00 0x22 0x04>;
				sprd,aon-glb = <0x2e>;
				bm-names = "AP\0WTLCP\0PUBCP\0WCN";
				bm-daps = <0x01 0x02 0x03 0x04>;
				aon_dap_index = <0x03>;
			};

			modem-dbg-log@40470000 {
				compatible = "sprd,dbg-log-sharkle";
				reg = <0x00 0x40470000 0x00 0x1000 0x00 0x403e0000 0x00 0x1000 0x00 0x40420000 0x00 0x1000>;
				sprd,syscon-pmu-apb = <0x3c>;
				sprd,syscon-aon-apb = <0x2e>;
				sprd,syscon-mm-ahb = <0x4e>;
				sprd,syscon-anlg-phy-g7 = <0x4f>;
			};
		};

		mm {
			compatible = "simple-bus";
			#address-cells = <0x02>;
			#size-cells = <0x02>;
			ranges;

			video-codec@21900000 {
				compatible = "sprd,sharkle-vsp";
				reg = <0x00 0x21900000 0x00 0xc000>;
				interrupts = <0x00 0x2b 0x04>;
				sprd,syscon-pmu-apb = <0x3c>;
				sprd,syscon-aon-apb = <0x2e>;
				sprd,syscon-mm-ahb = <0x21>;
				iommus = <0x50>;
				status = "ok";
				clock-names = "clk_ahb_gate_vsp_eb\0clk_vsp";
				clocks = <0x22 0x02 0x51>;
			};

			iommu@21901004 {
				compatible = "sprd,iommuexle-vsp";
				reg = <0x00 0x21901004 0x00 0x04 0x00 0x21901140 0x00 0x60 0x00 0x10000000 0x00 0x10000000>;
				reg_name = "mmu_interrupt_reg\0mmu_reg\0iova pool";
				status = "okay";
				#iommu-cells = <0x00>;
				linux,phandle = <0x50>;
				phandle = <0x50>;
			};

			dcam@60800000 {
				compatible = "sprd,dcam";
				reg = <0x00 0x60800000 0x00 0x1000 0x00 0x60801000 0x00 0x1000 0x00 0x60802000 0x00 0x1000 0x00 0x60803000 0x00 0x1000 0x00 0x60804000 0x00 0x4000 0x00 0x60808000 0x00 0x4000>;
				interrupts = <0x00 0x2d 0x04 0x00 0x42 0x04>;
				sprd,cam-ahb-syscon = <0x4e>;
				sprd,aon-apb-syscon = <0x2e>;
				sprd,syscon-pmu-apb = <0x3c>;
				sprd,isp = <0x52>;
				sprd,dcam-count = <0x02>;
				iommus = <0x53>;
				status = "okay";
				clock-names = "dcam_eb\0clk_gate_eb\0clk_cphy_cfg_gate_eb\0clk_mm_eb\0clk_mm_ahb\0clk_mm_ahb_parent\0dcam_clk\0dcam_clk_76m8\0dcam_clk_153m6\0dcam_clk_256m\0dcam_clk_307m2\0dcam_clk_parent";
				clocks = <0x54 0x00 0x54 0x06 0x08 0x00 0x3a 0x19 0x55 0x56 0x57 0x0a 0x56 0x58 0x59 0x59>;
			};

			iommu@60800000 {
				compatible = "sprd,iommuexle-dcam";
				reg = <0x00 0x60800000 0x00 0x2100 0x00 0x60802100 0x00 0x60 0x00 0x40000000 0x00 0x10000000>;
				reg_name = "mmu_interrupt_reg\0mmu_reg\0iova pool";
				status = "okay";
				#iommu-cells = <0x00>;
				linux,phandle = <0x53>;
				phandle = <0x53>;
			};

			isp@60a00000 {
				compatible = "sprd,isp";
				reg = <0x00 0x60a00000 0x00 0x100000>;
				interrupts = <0x00 0x2c 0x04 0x00 0x7d 0x04>;
				sprd,cam-ahb-syscon = <0x4e>;
				sprd,aon-apb-syscon = <0x2e>;
				sprd,isp-count = <0x01>;
				iommus = <0x5a>;
				status = "okay";
				clock-names = "isp_eb\0isp_axi_eb\0isp_clk\0isp_clk_128m\0isp_clk_256m\0isp_clk_307m2\0isp_clk_384m\0isp_clk_468m\0isp_clk_parent";
				clocks = <0x54 0x01 0x08 0x03 0x5b 0x31 0x58 0x59 0x2d 0x5c 0x5c>;
				linux,phandle = <0x52>;
				phandle = <0x52>;
			};

			iommu@60a00800 {
				compatible = "sprd,iommuexle-isp";
				reg = <0x00 0x00 0x00 0x40000 0x00 0x60a00800 0x00 0x400 0x00 0x50000000 0x00 0x10000000>;
				reg_name = "mmu_interrupt_reg\0mmu_reg\0iova pool";
				status = "okay";
				#iommu-cells = <0x00>;
				linux,phandle = <0x5a>;
				phandle = <0x5a>;
			};

			jpg-codec@60b00000 {
				compatible = "sprd,sharkle-jpg";
				reg = <0x00 0x60b00000 0x00 0x8000>;
				interrupts = <0x00 0x2a 0x04>;
				sprd,syscon-pmu-apb = <0x3c>;
				sprd,syscon-aon-apb = <0x2e>;
				sprd,syscon-mm-ahb = <0x4e>;
				iommus = <0x5d>;
				status = "ok";
				clock-names = "clk_mm_eb\0clk_axi_gate_jpg\0clk_ahb_gate_jpg_eb\0clk_jpg";
				clocks = <0x48 0x0e 0x54 0x06 0x54 0x05 0x5e>;
			};

			iommu@60b00024 {
				compatible = "sprd,iommuexle-jpg";
				reg = <0x00 0x60b00024 0x00 0x04 0x00 0x60b00100 0x00 0x400 0x00 0x30000000 0x00 0x10000000>;
				reg_name = "mmu_interrupt_reg\0mmu_reg\0iova pool";
				status = "okay";
				#iommu-cells = <0x00>;
				linux,phandle = <0x5d>;
				phandle = <0x5d>;
			};

			csi@60c00000 {
				compatible = "sprd,csi-controller";
				reg = <0x00 0x60c00000 0x00 0x1000>;
				interrupts = <0x00 0x28 0x04 0x00 0x29 0x04>;
				sprd,cam-ahb-syscon = <0x4e>;
				sprd,ana-apb-syscon = <0x2e>;
				sprd,anlg_phy_g7_controller = <0x4f>;
				sprd,csi-id = <0x00>;
				sprd,ip-version = <0x200>;
				status = "okay";
				clock-names = "clk_mipi_csi_gate_eb\0clk_csi_eb\0clk_csi_from";
				clocks = <0x08 0x04 0x54 0x03 0x5f 0x10>;
				linux,phandle = <0x62>;
				phandle = <0x62>;
			};

			cpp@61000000 {
				compatible = "sprd,cpp";
				reg = <0x00 0x61000000 0x00 0x1000>;
				interrupts = <0x00 0x1b 0x04>;
				sprd,cam-ahb-syscon = <0x4e>;
				sprd,ana-apb-syscon = <0x2e>;
				iommus = <0x60>;
				status = "okay";
				clock-names = "cpp_eb\0cpp_axi_eb";
				clocks = <0x54 0x02 0x48 0x0e>;
				ref-node = <0x52>;
			};

			iommu@61000010 {
				compatible = "sprd,iommuexle-cpp";
				reg = <0x00 0x61000010 0x00 0x04 0x00 0x61000200 0x00 0x60 0x00 0x60000000 0x00 0x8000000>;
				reg_name = "mmu_interrupt_reg\0mmu_reg\0iova pool";
				status = "okay";
				#iommu-cells = <0x00>;
				linux,phandle = <0x60>;
				phandle = <0x60>;
			};

			csi@61200000 {
				compatible = "sprd,csi-controller";
				reg = <0x00 0x61200000 0x00 0x1000>;
				interrupts = <0x00 0x47 0x04 0x00 0x48 0x04>;
				sprd,cam-ahb-syscon = <0x4e>;
				sprd,ana-apb-syscon = <0x2e>;
				sprd,anlg_phy_g7_controller = <0x4f>;
				sprd,csi-id = <0x01>;
				sprd,ip-version = <0x200>;
				status = "okay";
				clock-names = "clk_mipi_csi_gate_eb\0clk_csi_eb\0clk_csi_from";
				clocks = <0x08 0x05 0x54 0x04 0x61 0x10>;
				linux,phandle = <0x64>;
				phandle = <0x64>;
			};

			mipi-csi-phy0 {
				compatible = "sprd,mipi-csi-phy";
				sprd,phyid = <0x00>;
				status = "disabled";
			};

			mipi-csi-phy1 {
				compatible = "sprd,mipi-csi-phy";
				sprd,phyid = <0x01>;
				status = "okay";
				sprd,csi = <0x62>;

				port {

					endpoint {
						remote-enpoint = <0x63>;
						linux,phandle = <0x11>;
						phandle = <0x11>;
					};
				};
			};

			mipi-csi-phy0_m {
				compatible = "sprd,mipi-csi-phy";
				sprd,phyid = <0x02>;
				status = "okay";
				sprd,csi = <0x64>;

				port {

					endpoint {
						remote-enpoint = <0x65>;
						linux,phandle = <0x15>;
						phandle = <0x15>;
					};
				};
			};

			mipi-csi-phy0_s {
				compatible = "sprd,mipi-csi-phy";
				sprd,phyid = <0x03>;
				status = "okay";
				sprd,csi = <0x64>;

				port {

					endpoint {
						remote-enpoint = <0x66>;
						linux,phandle = <0x13>;
						phandle = <0x13>;
					};
				};
			};
		};

		pub {
			compatible = "simple-bus";
			#address-cells = <0x02>;
			#size-cells = <0x02>;
			ranges;

			syscon@30000000 {
				compatible = "sprd,sys-dmc-phy\0syscon";
				reg = <0x00 0x30000000 0x00 0x400>;
				sprd,sizel_off = <0x1b4>;
				sprd,sizeh_off = <0x1b8>;
			};

			ptm@30040000 {
				compatible = "sprd,ptm-sharkle";
				reg = <0x00 0x30040000 0x00 0x10000 0x00 0x1001000 0x00 0x1000 0x00 0x1003000 0x00 0x1000 0x00 0x1004000 0x00 0x1000>;
				interrupts = <0x00 0x56 0x04>;
				clock-names = "clk_cs\0cs_src";
				clocks = <0x67 0x09>;
				sprd,funnel-port = <0x04>;
				sprd,ddr-chn = <0x07>;
				sprd,chn-name = "MM\0GPU\0DISP\0A53\0AP/VSP/GSP\0WTLCP/PUBCP\0WCN/AON";
			};

			dmc-mpu@300e0000 {
				compatible = "sprd,dmc-mpu-r3p0";
				reg = <0x00 0x300e0000 0x00 0x10000>;
				interrupts = <0x00 0x3d 0x04>;
				sprd,channel-num = <0x08>;
				sprd,channel-names = "MM\0GPU\0DISP\0A53\0AP/VSP/GSP\0WTLCP/PUBCP\0WCN/AON\0SHARED";
				sprd,ranges = <0x00 0x00 0x00 0x00 0x00 0x00 0x00 0x00 0x00 0x00 0x00 0x00 0x00 0x00 0x00 0x00>;
				sprd,chn-config = <0x00 0x01 0x01 0x00 0x01 0x01 0x00 0x01 0x01 0x00 0x01 0x01 0x00 0x01 0x01 0x00 0x01 0x01 0x00 0x01 0x01 0x00 0x01 0x01>;
				sprd,id-config = <0x00 0x00 0x00 0x00 0x00 0x00 0x00 0x00 0x00 0x00 0x00 0x00 0x00 0x00 0x00 0x00 0x00 0x00 0x00 0x00 0x00 0x00 0x00 0x00>;
				sprd,panic;
				sprd,shared-chn = "MM";
				sprd,ddr-offset = <0x80000000>;
				status = "disabled";
			};
		};

		funnel@01001000 {
			compatible = "arm,coresight-funnel\0arm,primecell";
			reg = <0x00 0x1001000 0x00 0x1000>;
			clocks = <0x05>;
			clock-names = "apb_pclk";

			ports {
				#address-cells = <0x01>;
				#size-cells = <0x00>;

				port@0 {
					reg = <0x00>;

					endpoint {
						remote-endpoint = <0x68>;
						linux,phandle = <0x6a>;
						phandle = <0x6a>;
					};
				};

				port@1 {
					reg = <0x00>;

					endpoint {
						slave-mode;
						remote-endpoint = <0x69>;
						linux,phandle = <0x6b>;
						phandle = <0x6b>;
					};
				};
			};
		};

		tmc@01003000 {
			compatible = "arm,coresight-tmc\0arm,primecell";
			reg = <0x00 0x1003000 0x00 0x1000>;
			clocks = <0x05>;
			clock-names = "apb_pclk";

			port {

				endpoint {
					slave-mode;
					remote-endpoint = <0x6a>;
					linux,phandle = <0x68>;
					phandle = <0x68>;
				};
			};
		};

		ts@01006000 {
			compatible = "arm,coresight-ts\0arm,primecell";
			reg = <0x00 0x1006000 0x00 0x1000>;
		};

		funnel@01a00000 {
			compatible = "arm,coresight-funnel\0arm,primecell";
			reg = <0x00 0x1a00000 0x00 0x1000>;
			clocks = <0x05>;
			clock-names = "apb_pclk";

			ports {
				#address-cells = <0x01>;
				#size-cells = <0x00>;

				port@0 {
					reg = <0x00>;

					endpoint {
						remote-endpoint = <0x6b>;
						linux,phandle = <0x69>;
						phandle = <0x69>;
					};
				};

				port@1 {
					reg = <0x00>;

					endpoint {
						slave-mode;
						remote-endpoint = <0x6c>;
						linux,phandle = <0x71>;
						phandle = <0x71>;
					};
				};

				port@2 {
					reg = <0x01>;

					endpoint {
						slave-mode;
						remote-endpoint = <0x6d>;
						linux,phandle = <0x73>;
						phandle = <0x73>;
					};
				};

				port@3 {
					reg = <0x02>;

					endpoint {
						slave-mode;
						remote-endpoint = <0x6e>;
						linux,phandle = <0x75>;
						phandle = <0x75>;
					};
				};

				port@4 {
					reg = <0x03>;

					endpoint {
						slave-mode;
						remote-endpoint = <0x6f>;
						linux,phandle = <0x77>;
						phandle = <0x77>;
					};
				};
			};
		};

		etm@01c40000 {
			compatible = "arm,coresight-etm4x\0arm,primecell";
			reg = <0x00 0x1c40000 0x00 0x1000>;
			cpu = <0x70>;
			clocks = <0x05 0x67 0x58>;
			clock-names = "apb_pclk\0clk_cs\0cs_src";

			port {

				endpoint {
					remote-endpoint = <0x71>;
					linux,phandle = <0x6c>;
					phandle = <0x6c>;
				};
			};
		};

		etm@01d40000 {
			compatible = "arm,coresight-etm4x\0arm,primecell";
			reg = <0x00 0x1d40000 0x00 0x1000>;
			cpu = <0x72>;
			clocks = <0x05 0x67 0x58>;
			clock-names = "apb_pclk\0clk_cs\0cs_src";

			port {

				endpoint {
					remote-endpoint = <0x73>;
					linux,phandle = <0x6d>;
					phandle = <0x6d>;
				};
			};
		};

		etm@01e40000 {
			compatible = "arm,coresight-etm4x\0arm,primecell";
			reg = <0x00 0x1e40000 0x00 0x1000>;
			cpu = <0x74>;
			clocks = <0x05 0x67 0x58>;
			clock-names = "apb_pclk\0clk_cs\0cs_src";

			port {

				endpoint {
					remote-endpoint = <0x75>;
					linux,phandle = <0x6e>;
					phandle = <0x6e>;
				};
			};
		};

		etm@01f40000 {
			compatible = "arm,coresight-etm4x\0arm,primecell";
			reg = <0x00 0x1f40000 0x00 0x1000>;
			cpu = <0x76>;
			clocks = <0x05 0x67 0x58>;
			clock-names = "apb_pclk\0clk_cs\0cs_src";

			port {

				endpoint {
					remote-endpoint = <0x77>;
					linux,phandle = <0x6f>;
					phandle = <0x6f>;
				};
			};
		};

		ext-26m {
			compatible = "fixed-clock";
			#clock-cells = <0x00>;
			clock-frequency = <0x18cba80>;
			clock-output-names = "ext_26m";
			linux,phandle = <0x05>;
			phandle = <0x05>;
		};

		ext-13m {
			compatible = "fixed-clock";
			#clock-cells = <0x00>;
			clock-frequency = <0xc65d40>;
			clock-output-names = "ext_13m";
			linux,phandle = <0x99>;
			phandle = <0x99>;
		};

		ext-6m5 {
			compatible = "fixed-clock";
			#clock-cells = <0x00>;
			clock-frequency = <0x632ea0>;
			clock-output-names = "ext_6m5";
			linux,phandle = <0x98>;
			phandle = <0x98>;
		};

		ext-4m3 {
			compatible = "fixed-clock";
			#clock-cells = <0x00>;
			clock-frequency = <0x419ce0>;
			clock-output-names = "ext_4m3";
			linux,phandle = <0x9a>;
			phandle = <0x9a>;
		};

		ext-4m {
			compatible = "fixed-clock";
			#clock-cells = <0x00>;
			clock-frequency = "\0=\t";
			clock-output-names = "ext_4m";
		};

		ext-250k {
			compatible = "fixed-clock";
			#clock-cells = <0x00>;
			clock-frequency = <0x3d090>;
			clock-output-names = "ext_250k";
			linux,phandle = <0x97>;
			phandle = <0x97>;
		};

		ext-32k {
			compatible = "fixed-clock";
			#clock-cells = <0x00>;
			clock-frequency = <0x8000>;
			clock-output-names = "ext_32k";
			linux,phandle = <0x95>;
			phandle = <0x95>;
		};

		ext-26m-rf1 {
			compatible = "fixed-clock";
			#clock-cells = <0x00>;
			clock-frequency = <0x18cba80>;
			clock-output-names = "ext_26m_rf1";
		};

		ext-1m {
			compatible = "fixed-clock";
			#clock-cells = <0x00>;
			clock-frequency = <0xf4240>;
			clock-output-names = "ext_1m";
			linux,phandle = <0x92>;
			phandle = <0x92>;
		};

		ext-2m {
			compatible = "fixed-clock";
			#clock-cells = <0x00>;
			clock-frequency = <0x1e8480>;
			clock-output-names = "ext_2m";
		};

		ext-rc0-4m {
			compatible = "fixed-clock";
			#clock-cells = <0x00>;
			clock-frequency = "\0=\t";
			clock-output-names = "ext_rc0_4m";
		};

		clk-pad {
			compatible = "fixed-clock";
			#clock-cells = <0x00>;
			clock-frequency = <0x3d09000>;
			clock-output-names = "clk_pad";
		};

		clk@40410008 {
			compatible = "sprd,sc1000-gates-clock";
			#clock-cells = <0x01>;
			sprd,gates-msk = <0x100>;
			reg = <0x00 0x40410008 0x00 0x3000>;
			clocks = <0x05>;
			clock-output-names = "clk_audio_gate";
			linux,phandle = <0x9f>;
			phandle = <0x9f>;
		};

		clk@402b0088 {
			compatible = "sprd,sc1000-hppll-gates-clock";
			#clock-cells = <0x01>;
			sprd,gates-msk = <0x01>;
			reg = <0x00 0x402b0088 0x00 0x3000>;
			clocks = <0x05>;
			clock-output-names = "clk_isppll_gate";
			linux,phandle = <0x7a>;
			phandle = <0x7a>;
		};

		clk@402b0094 {
			compatible = "sprd,sc1000-hppll-gates-clock";
			#clock-cells = <0x01>;
			sprd,gates-msk = <0x01>;
			reg = <0x00 0x402b0094 0x00 0x3000>;
			clocks = <0x05>;
			clock-output-names = "clk_mpll_gate";
			linux,phandle = <0x7c>;
			phandle = <0x7c>;
		};

		clk@402b0098 {
			compatible = "sprd,sc1000-hppll-gates-clock";
			#clock-cells = <0x01>;
			sprd,gates-msk = <0x01>;
			reg = <0x00 0x402b0098 0x00 0x3000>;
			clocks = <0x05>;
			clock-output-names = "clk_dpll_gate";
			linux,phandle = <0x7b>;
			phandle = <0x7b>;
		};

		clk@402b009c {
			compatible = "sprd,sc1000-hppll-gates-clock";
			#clock-cells = <0x01>;
			sprd,gates-msk = <0x01>;
			reg = <0x00 0x402b009c 0x00 0x3000>;
			clocks = <0x05>;
			clock-output-names = "clk_lpll_gate";
			linux,phandle = <0x78>;
			phandle = <0x78>;
		};

		clk@402b00a8 {
			compatible = "sprd,sc1000-hppll-gates-clock";
			#clock-cells = <0x01>;
			sprd,gates-msk = <0x01>;
			reg = <0x00 0x402b00a8 0x00 0x3000>;
			clocks = <0x05>;
			clock-output-names = "clk_gpll_gate";
			linux,phandle = <0x79>;
			phandle = <0x79>;
		};

		clk@403c000c {
			compatible = "sprd,sc9835-adjustable-pll-clock";
			#clock-cells = <0x00>;
			reg = <0x00 0x403c000c 0x00 0x04 0x00 0x403c0010 0x00 0x04>;
			clocks = <0x05>;
			clock-output-names = "clk_twpll";
			linux,phandle = <0x82>;
			phandle = <0x82>;
		};

		clk@403c001c {
			compatible = "sprd,sc9835-adjustable-pll-clock";
			#clock-cells = <0x00>;
			reg = <0x00 0x403c001c 0x00 0x04 0x00 0x403c0020 0x00 0x04>;
			clocks = <0x78 0x00>;
			clock-output-names = "clk_lpll";
			linux,phandle = <0x81>;
			phandle = <0x81>;
		};

		clk@403c002c {
			compatible = "sprd,sc9835-adjustable-pll-clock";
			#clock-cells = <0x00>;
			reg = <0x00 0x403c002c 0x00 0x04 0x00 0x403c0030 0x00 0x04 0x00 0x403c0034 0x00 0x04>;
			clocks = <0x79 0x00>;
			clock-output-names = "clk_gpll";
			linux,phandle = <0x9b>;
			phandle = <0x9b>;
		};

		clk@403c003c {
			compatible = "sprd,sc9835-adjustable-pll-clock";
			#clock-cells = <0x00>;
			reg = <0x00 0x403c003c 0x00 0x04 0x00 0x403c0040 0x00 0x04>;
			clocks = <0x7a 0x00>;
			clock-output-names = "clk_isppll";
			linux,phandle = <0x83>;
			phandle = <0x83>;
		};

		clk@403d0000 {
			compatible = "sprd,sc9835-adjustable-pll-clock";
			#clock-cells = <0x00>;
			reg = <0x00 0x403d0000 0x00 0x04 0x00 0x403d0004 0x00 0x04>;
			clocks = <0x7b 0x00>;
			clock-output-names = "clk_dpll";
			linux,phandle = <0x7e>;
			phandle = <0x7e>;
		};

		clk@403f0000 {
			compatible = "sprd,sc9835-adjustable-pll-clock";
			#clock-cells = <0x00>;
			reg = <0x00 0x403f0000 0x00 0x04 0x00 0x403f0004 0x00 0x04>;
			clocks = <0x7c 0x00>;
			clock-output-names = "clk_mpll";
			linux,phandle = <0x7d>;
			phandle = <0x7d>;
		};

		clk@40410014 {
			compatible = "sprd,sc9835-adjustable-pll-clock";
			#clock-cells = <0x00>;
			reg = <0x00 0x40410014 0x00 0x04 0x00 0x40410018 0x00 0x04>;
			clocks = <0x05>;
			clock-output-names = "clk_rpll";
			linux,phandle = <0x7f>;
			phandle = <0x7f>;
		};

		clk-mpll-50m {
			compatible = "fixed-factor-clock";
			#clock-cells = <0x00>;
			clock-mult = <0x01>;
			clock-div = <0x12>;
			clocks = <0x7d>;
			clock-output-names = "clk_mpll_50m";
		};

		clk-dpll-40m {
			compatible = "fixed-factor-clock";
			#clock-cells = <0x00>;
			clock-mult = <0x01>;
			clock-div = <0x20>;
			clocks = <0x7e>;
			clock-output-names = "clk_dpll_40m";
		};

		clk@4041001c {
			compatible = "sprd,sc1000-gates-clock";
			#clock-cells = <0x01>;
			reg = <0x00 0x4041001c 0x00 0x3000>;
			sprd,gates-msk = <0x100>;
			clocks = <0x7f>;
			clock-output-names = "clk_rpll_d1_en";
			linux,phandle = <0x80>;
			phandle = <0x80>;
		};

		clk-rpll-390m {
			compatible = "fixed-factor-clock";
			#clock-cells = <0x00>;
			clock-mult = <0x01>;
			clock-div = <0x02>;
			clocks = <0x80 0x08>;
			clock-output-names = "clk_rpll_390m";
			linux,phandle = <0x24>;
			phandle = <0x24>;
		};

		clk-rpll-260m {
			compatible = "fixed-factor-clock";
			#clock-cells = <0x00>;
			clock-mult = <0x01>;
			clock-div = <0x03>;
			clocks = <0x7f>;
			clock-output-names = "clk_rpll_260m";
			linux,phandle = <0x91>;
			phandle = <0x91>;
		};

		clk-rpll-195m {
			compatible = "fixed-factor-clock";
			#clock-cells = <0x00>;
			clock-mult = <0x01>;
			clock-div = <0x04>;
			clocks = <0x7f>;
			clock-output-names = "clk_rpll_195m";
			linux,phandle = <0x8e>;
			phandle = <0x8e>;
		};

		clk-rpll-26m {
			compatible = "fixed-factor-clock";
			#clock-cells = <0x00>;
			clock-mult = <0x01>;
			clock-div = <0x1e>;
			clocks = <0x7f>;
			clock-output-names = "clk_rpll_26m";
			linux,phandle = <0x96>;
			phandle = <0x96>;
		};

		clk-lpll-409m6 {
			compatible = "fixed-factor-clock";
			#clock-cells = <0x00>;
			clock-mult = <0x01>;
			clock-div = <0x03>;
			clocks = <0x81>;
			clock-output-names = "clk_lpll_409m6";
			linux,phandle = <0x93>;
			phandle = <0x93>;
		};

		clk-lpll-245m76 {
			compatible = "fixed-factor-clock";
			#clock-cells = <0x00>;
			clock-mult = <0x01>;
			clock-div = <0x05>;
			clocks = <0x81>;
			clock-output-names = "clk_lpll_245m76";
			linux,phandle = <0x90>;
			phandle = <0x90>;
		};

		clk-twpll-768m {
			compatible = "fixed-factor-clock";
			#clock-cells = <0x00>;
			clock-mult = <0x01>;
			clock-div = <0x02>;
			clocks = <0x82>;
			clock-output-names = "clk_twpll_768m";
			linux,phandle = <0x86>;
			phandle = <0x86>;
		};

		clk-twpll-384m {
			compatible = "fixed-factor-clock";
			#clock-cells = <0x00>;
			clock-mult = <0x01>;
			clock-div = <0x04>;
			clocks = <0x82>;
			clock-output-names = "clk_twpll_384m";
			linux,phandle = <0x2d>;
			phandle = <0x2d>;
		};

		clk-twpll-192m {
			compatible = "fixed-factor-clock";
			#clock-cells = <0x00>;
			clock-mult = <0x01>;
			clock-div = <0x08>;
			clocks = <0x82>;
			clock-output-names = "clk_twpll_192m";
			linux,phandle = <0x1c>;
			phandle = <0x1c>;
		};

		clk-twpll-96m {
			compatible = "fixed-factor-clock";
			#clock-cells = <0x00>;
			clock-mult = <0x01>;
			clock-div = <0x10>;
			clocks = <0x82>;
			clock-output-names = "clk_twpll_96m";
			linux,phandle = <0x09>;
			phandle = <0x09>;
		};

		clk-twpll-48m {
			compatible = "fixed-factor-clock";
			#clock-cells = <0x00>;
			clock-mult = <0x01>;
			clock-div = <0x20>;
			clocks = <0x82>;
			clock-output-names = "clk_twpll_48m";
			linux,phandle = <0x0b>;
			phandle = <0x0b>;
		};

		clk-twpll-24m {
			compatible = "fixed-factor-clock";
			#clock-cells = <0x00>;
			clock-mult = <0x01>;
			clock-div = <0x40>;
			clocks = <0x82>;
			clock-output-names = "clk_twpll_24m";
			linux,phandle = <0x8a>;
			phandle = <0x8a>;
		};

		clk-twpll-12m {
			compatible = "fixed-factor-clock";
			#clock-cells = <0x00>;
			clock-mult = <0x01>;
			clock-div = <0x80>;
			clocks = <0x82>;
			clock-output-names = "clk_twpll_12m";
			linux,phandle = <0x89>;
			phandle = <0x89>;
		};

		clk-twpll-512m {
			compatible = "fixed-factor-clock";
			#clock-cells = <0x00>;
			clock-mult = <0x01>;
			clock-div = <0x03>;
			clocks = <0x82>;
			clock-output-names = "clk_twpll_512m";
			linux,phandle = <0x85>;
			phandle = <0x85>;
		};

		clk-twpll-256m {
			compatible = "fixed-factor-clock";
			#clock-cells = <0x00>;
			clock-mult = <0x01>;
			clock-div = <0x06>;
			clocks = <0x82>;
			clock-output-names = "clk_twpll_256m";
			linux,phandle = <0x58>;
			phandle = <0x58>;
		};

		clk-twpll-128m {
			compatible = "fixed-factor-clock";
			#clock-cells = <0x00>;
			clock-mult = <0x01>;
			clock-div = <0x0c>;
			clocks = <0x82>;
			clock-output-names = "clk_twpll_128m";
			linux,phandle = <0x31>;
			phandle = <0x31>;
		};

		clk-twpll-64m {
			compatible = "fixed-factor-clock";
			#clock-cells = <0x00>;
			clock-mult = <0x01>;
			clock-div = <0x18>;
			clocks = <0x82>;
			clock-output-names = "clk_twpll_64m";
			linux,phandle = <0x88>;
			phandle = <0x88>;
		};

		clk-twpll-307m2 {
			compatible = "fixed-factor-clock";
			#clock-cells = <0x00>;
			clock-mult = <0x01>;
			clock-div = <0x05>;
			clocks = <0x82>;
			clock-output-names = "clk_twpll_307m2";
			linux,phandle = <0x59>;
			phandle = <0x59>;
		};

		clk-twpll-219m4 {
			compatible = "fixed-factor-clock";
			#clock-cells = <0x00>;
			clock-mult = <0x01>;
			clock-div = <0x07>;
			clocks = <0x82>;
			clock-output-names = "clk_twpll_219m4";
			linux,phandle = <0x8f>;
			phandle = <0x8f>;
		};

		clk-twpll-170m6 {
			compatible = "fixed-factor-clock";
			#clock-cells = <0x00>;
			clock-mult = <0x01>;
			clock-div = <0x09>;
			clocks = <0x82>;
			clock-output-names = "clk_twpll_170m6";
			linux,phandle = <0x8d>;
			phandle = <0x8d>;
		};

		clk-twpll-153m6 {
			compatible = "fixed-factor-clock";
			#clock-cells = <0x00>;
			clock-mult = <0x01>;
			clock-div = <0x0a>;
			clocks = <0x82>;
			clock-output-names = "clk_twpll_153m6";
			linux,phandle = <0x56>;
			phandle = <0x56>;
		};

		clk-twpll-76m8 {
			compatible = "fixed-factor-clock";
			#clock-cells = <0x00>;
			clock-mult = <0x01>;
			clock-div = <0x14>;
			clocks = <0x82>;
			clock-output-names = "clk_twpll_76m8";
			linux,phandle = <0x0a>;
			phandle = <0x0a>;
		};

		clk-twpll-51m2 {
			compatible = "fixed-factor-clock";
			#clock-cells = <0x00>;
			clock-mult = <0x01>;
			clock-div = <0x1e>;
			clocks = <0x82>;
			clock-output-names = "clk_twpll_51m2";
			linux,phandle = <0x8c>;
			phandle = <0x8c>;
		};

		clk-twpll-38m4 {
			compatible = "fixed-factor-clock";
			#clock-cells = <0x00>;
			clock-mult = <0x01>;
			clock-div = <0x28>;
			clocks = <0x82>;
			clock-output-names = "clk_twpll_38m4";
			linux,phandle = <0x94>;
			phandle = <0x94>;
		};

		clk-twpll-19m2 {
			compatible = "fixed-factor-clock";
			#clock-cells = <0x00>;
			clock-mult = <0x01>;
			clock-div = <0x50>;
			clocks = <0x82>;
			clock-output-names = "clk_twpll_19m2";
		};

		clk-twpll-468m {
			compatible = "fixed-factor-clock";
			#clock-cells = <0x00>;
			clock-mult = <0x01>;
			clock-div = <0x02>;
			clocks = <0x83>;
			clock-output-names = "clk_isppll_468m";
			linux,phandle = <0x5c>;
			phandle = <0x5c>;
		};

		clk@20e00000 {
			compatible = "sprd,sc1000-gates-clock";
			#clock-cells = <0x01>;
			reg = <0x00 0x20e00000 0x00 0x3000>;
			sprd,gates-msk = <0x38802fff>;
			clocks = <0x84>;
			clock-output-names = "dsi_eb\0dispc_eb\0vsp_eb\0gsp_eb\0otg_eb\0dma_pub_eb\0ce_pub_eb\0ahb_ckg_eb\0sdio0_eb\0sdio1_eb\0nandc_eb\0emmc_eb\0spinlock_eb\0ce_efuse_eb\0emmc_32k_eb\0sdio0_32k_eb\0sdio1_32k_eb";
			linux,phandle = <0x22>;
			phandle = <0x22>;
		};

		clk-mcu {
			compatible = "sprd,composite-clock";
			#clock-cells = <0x00>;
			reg = <0x00 0x20e00054 0x00 0x04 0x00 0x20e00038 0x00 0x04>;
			sprd,mux-msk = <0x03>;
			sprd,div-msk = <0x70>;
			clocks = <0x05 0x85 0x86 0x7d>;
			clock-output-names = "clk_mcu";
			linux,phandle = <0x87>;
			phandle = <0x87>;
		};

		clk-ca53-axi {
			compatible = "sprd,divider-clock";
			#clock-cells = <0x00>;
			sprd,div-msk = <0x700>;
			clocks = <0x87>;
			clock-output-names = "clk_ca53_axi";
		};

		clk-ap-dbg {
			compatible = "sprd,divider-clock";
			#clock-cells = <0x00>;
			sprd,div-msk = <0x70000>;
			clocks = <0x87>;
			clock-output-names = "clk_ap_dbg";
		};

		clk@21500020 {
			compatible = "sprd,muxed-clock";
			#clock-cells = <0x00>;
			reg = <0x00 0x21500020 0x00 0x04>;
			sprd,mux-msk = <0x03>;
			clocks = <0x05 0x88 0x09 0x31>;
			clock-output-names = "clk_ap_apb";
			linux,phandle = <0x8b>;
			phandle = <0x8b>;
		};

		clk@21500024 {
			compatible = "sprd,composite-clock";
			#clock-cells = <0x00>;
			reg = <0x00 0x21500024 0x00 0x04>;
			sprd,mux-msk = <0x03>;
			sprd,div-msk = <0x700>;
			clocks = <0x05 0x58 0x59>;
			clock-output-names = "clk_nandc_ecc";
			linux,phandle = <0xac>;
			phandle = <0xac>;
		};

		clk@21500028 {
			compatible = "sprd,muxed-clock";
			#clock-cells = <0x00>;
			reg = <0x00 0x21500028 0x00 0x04>;
			sprd,mux-msk = <0x01>;
			clocks = <0x89 0x8a>;
			clock-output-names = "clk_otg_ref";
			linux,phandle = <0xb0>;
			phandle = <0xb0>;
		};

		clk@2150002c {
			compatible = "sprd,gates-clock";
			#clock-cells = <0x01>;
			reg = <0x00 0x2150002c 0x00 0x04>;
			sprd,gates-msk = <0x10000>;
			clocks = <0x8b>;
			clock-output-names = "clk_otg_utmi";
		};

		clk@21500030 {
			compatible = "sprd,composite-clock";
			#clock-cells = <0x00>;
			reg = <0x00 0x21500030 0x00 0x04>;
			sprd,mux-msk = <0x03>;
			sprd,div-msk = <0x700>;
			clocks = <0x05 0x0b 0x8c 0x09>;
			clock-output-names = "clk_uart1";
			linux,phandle = <0x04>;
			phandle = <0x04>;
		};

		clk@21500034 {
			compatible = "sprd,composite-clock";
			#clock-cells = <0x00>;
			reg = <0x00 0x21500034 0x00 0x04>;
			sprd,mux-msk = <0x03>;
			sprd,div-msk = <0x700>;
			clocks = <0x05 0x0b 0x8c 0x56>;
			clock-output-names = "clk_i2c0";
			linux,phandle = <0x06>;
			phandle = <0x06>;
		};

		clk@21500038 {
			compatible = "sprd,composite-clock";
			#clock-cells = <0x00>;
			reg = <0x00 0x21500038 0x00 0x04>;
			sprd,mux-msk = <0x03>;
			sprd,div-msk = <0x700>;
			clocks = <0x05 0x0b 0x8c 0x56>;
			clock-output-names = "clk_i2c1";
			linux,phandle = <0x14>;
			phandle = <0x14>;
		};

		clk@2150003c {
			compatible = "sprd,composite-clock";
			#clock-cells = <0x00>;
			reg = <0x00 0x2150003c 0x00 0x04>;
			sprd,mux-msk = <0x03>;
			sprd,div-msk = <0x700>;
			clocks = <0x05 0x0b 0x8c 0x56>;
			clock-output-names = "clk_i2c2";
			linux,phandle = <0x16>;
			phandle = <0x16>;
		};

		clk@21500040 {
			compatible = "sprd,composite-clock";
			#clock-cells = <0x00>;
			reg = <0x00 0x21500040 0x00 0x04>;
			sprd,mux-msk = <0x03>;
			sprd,div-msk = <0x700>;
			clocks = <0x05 0x0b 0x8c 0x56>;
			clock-output-names = "clk_i2c3";
			linux,phandle = <0x17>;
			phandle = <0x17>;
		};

		clk@21500044 {
			compatible = "sprd,composite-clock";
			#clock-cells = <0x00>;
			reg = <0x00 0x21500044 0x00 0x04>;
			sprd,mux-msk = <0x03>;
			sprd,div-msk = <0x700>;
			clocks = <0x05 0x0b 0x8c 0x56>;
			clock-output-names = "clk_i2c4";
			linux,phandle = <0x18>;
			phandle = <0x18>;
		};

		clk@21500048 {
			compatible = "sprd,composite-clock";
			#clock-cells = <0x00>;
			reg = <0x00 0x21500048 0x00 0x04>;
			sprd,mux-msk = <0x03>;
			sprd,div-msk = <0x700>;
			clocks = <0x05 0x31 0x56 0x1c>;
			clock-output-names = "clk_spi0";
			linux,phandle = <0x1b>;
			phandle = <0x1b>;
		};

		clk@2150004c {
			compatible = "sprd,composite-clock";
			#clock-cells = <0x00>;
			reg = <0x00 0x2150004c 0x00 0x04>;
			sprd,mux-msk = <0x03>;
			sprd,div-msk = <0x700>;
			clocks = <0x05 0x31 0x56 0x1c>;
			clock-output-names = "clk_spi2";
			linux,phandle = <0x1f>;
			phandle = <0x1f>;
		};

		clk@21500050 {
			compatible = "sprd,composite-clock";
			#clock-cells = <0x00>;
			reg = <0x00 0x21500050 0x00 0x04>;
			sprd,mux-msk = <0x03>;
			sprd,div-msk = <0x700>;
			clocks = <0x05 0x31 0x56 0x1c>;
			clock-output-names = "clk_hs_spi";
			linux,phandle = <0x1e>;
			phandle = <0x1e>;
		};

		clk@21500054 {
			compatible = "sprd,composite-clock";
			#clock-cells = <0x00>;
			reg = <0x00 0x21500054 0x00 0x04>;
			sprd,mux-msk = <0x03>;
			sprd,div-msk = <0x700>;
			clocks = <0x05 0x31 0x56>;
			clock-output-names = "clk_iis0";
			linux,phandle = <0xb1>;
			phandle = <0xb1>;
		};

		clk@21500058 {
			compatible = "sprd,muxed-clock";
			#clock-cells = <0x00>;
			reg = <0x00 0x21500058 0x00 0x04>;
			sprd,mux-msk = <0x03>;
			clocks = <0x05 0x09 0x1c 0x58>;
			clock-output-names = "clk_ce";
			linux,phandle = <0xad>;
			phandle = <0xad>;
		};

		clk@21500078 {
			compatible = "sprd,composite-clock";
			#clock-cells = <0x00>;
			reg = <0x00 0x21500078 0x00 0x04>;
			sprd,mux-msk = <0x0f>;
			sprd,div-msk = <0xf00>;
			clocks = <0x05 0x56 0x8d 0x8e 0x8f 0x90 0x91 0x59 0x24>;
			clock-output-names = "clk_nandc_2x";
			linux,phandle = <0xae>;
			phandle = <0xae>;
		};

		clk@21500080 {
			compatible = "sprd,muxed-clock";
			#clock-cells = <0x00>;
			reg = <0x00 0x21500080 0x00 0x04>;
			sprd,mux-msk = <0x07>;
			clocks = <0x92 0x05 0x59 0x2d 0x24 0x93>;
			clock-output-names = "clk_sdio0_2x";
			linux,phandle = <0x26>;
			phandle = <0x26>;
		};

		clk@21500088 {
			compatible = "sprd,muxed-clock";
			#clock-cells = <0x00>;
			reg = <0x00 0x21500088 0x00 0x04>;
			sprd,mux-msk = <0x07>;
			clocks = <0x92 0x05 0x59 0x2d 0x24 0x93>;
			clock-output-names = "clk_sdio1_2x";
			linux,phandle = <0xaf>;
			phandle = <0xaf>;
		};

		clk@21500090 {
			compatible = "sprd,muxed-clock";
			#clock-cells = <0x00>;
			reg = <0x00 0x21500090 0x00 0x04>;
			sprd,mux-msk = <0x07>;
			clocks = <0x92 0x05 0x59 0x2d 0x24 0x93>;
			clock-output-names = "clk_emmc_2x";
			linux,phandle = <0x23>;
			phandle = <0x23>;
		};

		clk@21500098 {
			compatible = "sprd,muxed-clock";
			#clock-cells = <0x00>;
			reg = <0x00 0x21500098 0x00 0x04>;
			sprd,mux-msk = <0x03>;
			clocks = <0x0a 0x31 0x58 0x59>;
			clock-output-names = "clk_vsp";
			linux,phandle = <0x51>;
			phandle = <0x51>;
		};

		clk@2150009c {
			compatible = "sprd,muxed-clock";
			#clock-cells = <0x00>;
			reg = <0x00 0x2150009c 0x00 0x04>;
			sprd,mux-msk = <0x03>;
			clocks = <0x56 0x1c 0x58 0x2d>;
			clock-output-names = "clk_gsp";
			linux,phandle = <0x2c>;
			phandle = <0x2c>;
		};

		clk@215000a0 {
			compatible = "sprd,muxed-clock";
			#clock-cells = <0x00>;
			reg = <0x00 0x215000a0 0x00 0x04>;
			sprd,mux-msk = <0x03>;
			clocks = <0x56 0x1c 0x58 0x2d>;
			clock-output-names = "clk_dispc0";
			linux,phandle = <0x32>;
			phandle = <0x32>;
		};

		clk@215000a4 {
			compatible = "sprd,composite-clock";
			#clock-cells = <0x00>;
			reg = <0x00 0x215000a4 0x00 0x04>;
			sprd,mux-msk = <0x03>;
			sprd,div-msk = <0xf00>;
			clocks = <0x09 0x31 0x56>;
			clock-output-names = "clk_dispc0_dpi";
			linux,phandle = <0x33>;
			phandle = <0x33>;
		};

		clk@215000a8 {
			compatible = "sprd,gates-clock";
			#clock-cells = <0x01>;
			reg = <0x00 0x215000a8 0x00 0x04>;
			sprd,gates-msk = <0x10000>;
			clocks = <0x8b>;
			clock-output-names = "clk_dsi_rxesc";
		};

		clk@215000ac {
			compatible = "sprd,gates-clock";
			#clock-cells = <0x01>;
			reg = <0x00 0x215000ac 0x00 0x04>;
			sprd,gates-msk = <0x10000>;
			clocks = <0x8b>;
			clock-output-names = "clk_dsi_lanebyte";
		};

		clk@402d0220 {
			compatible = "sprd,composite-clock";
			#clock-cells = <0x00>;
			reg = <0x00 0x402d0220 0x00 0x04>;
			sprd,mux-msk = <0x03>;
			sprd,div-msk = <0x300>;
			clocks = <0x05 0x0a 0x09 0x31>;
			clock-output-names = "clk_aon_apb";
			linux,phandle = <0x9c>;
			phandle = <0x9c>;
		};

		clk@402d0224 {
			compatible = "sprd,muxed-clock";
			#clock-cells = <0x00>;
			reg = <0x00 0x402d0224 0x00 0x04>;
			sprd,mux-msk = <0x03>;
			clocks = <0x05 0x94 0x8c>;
			clock-output-names = "clk_adi";
		};

		clk@402e0088 {
			compatible = "sprd,composite-clock";
			#clock-cells = <0x00>;
			reg = <0x00 0x402e0088 0x00 0x04>;
			sprd,mux-msk = <0x01>;
			sprd,div-msk = <0xf0000>;
			clocks = <0x95 0x05>;
			clock-output-names = "clk_aux0";
		};

		clk-aux1 {
			compatible = "sprd,composite-clock";
			#clock-cells = <0x00>;
			reg = <0x00 0x402e0088 0x00 0x04>;
			sprd,mux-msk = <0x10>;
			sprd,div-msk = <0xf00000>;
			clocks = <0x95 0x05>;
			clock-output-names = "clk_aux1";
		};

		clk@402d0238 {
			compatible = "sprd,muxed-clock";
			#clock-cells = <0x00>;
			reg = <0x00 0x402d0238 0x00 0x04>;
			sprd,mux-msk = <0x03>;
			clocks = <0x95 0x05 0x96 0x0b>;
			clock-output-names = "clk_pwm0";
		};

		clk@402d023c {
			compatible = "sprd,muxed-clock";
			#clock-cells = <0x00>;
			reg = <0x00 0x402d023c 0x00 0x04>;
			sprd,mux-msk = <0x03>;
			clocks = <0x95 0x05 0x96 0x0b>;
			clock-output-names = "clk_pwm1";
			linux,phandle = <0x49>;
			phandle = <0x49>;
		};

		clk@402d0240 {
			compatible = "sprd,muxed-clock";
			#clock-cells = <0x00>;
			reg = <0x00 0x402d0240 0x00 0x04>;
			sprd,mux-msk = <0x03>;
			clocks = <0x95 0x05 0x96 0x0b>;
			clock-output-names = "clk_pwm2";
		};

		clk@402d0244 {
			compatible = "sprd,muxed-clock";
			#clock-cells = <0x00>;
			reg = <0x00 0x402d0244 0x00 0x04>;
			sprd,mux-msk = <0x03>;
			clocks = <0x95 0x05 0x96 0x0b>;
			clock-output-names = "clk_pwm3";
		};

		clk@402d0258 {
			compatible = "sprd,muxed-clock";
			#clock-cells = <0x00>;
			reg = <0x00 0x402d0258 0x00 0x04>;
			sprd,mux-msk = <0x01>;
			clocks = <0x95 0x97>;
			clock-output-names = "clk_thm0";
		};

		clk@402d025c {
			compatible = "sprd,muxed-clock";
			#clock-cells = <0x00>;
			reg = <0x00 0x402d025c 0x00 0x04>;
			sprd,mux-msk = <0x01>;
			clocks = <0x95 0x97>;
			clock-output-names = "clk_thm1";
		};

		clk@402d0264 {
			compatible = "sprd,muxed-clock";
			#clock-cells = <0x00>;
			reg = <0x00 0x402d0264 0x00 0x04>;
			sprd,mux-msk = <0x03>;
			clocks = <0x05 0x94 0x8c>;
			clock-output-names = "clk_audif";
		};

		clk@402d026c {
			compatible = "sprd,gates-clock";
			#clock-cells = <0x01>;
			reg = <0x00 0x402d026c 0x00 0x04>;
			sprd,gates-msk = <0x10000>;
			clocks = <0x8b>;
			clock-output-names = "clk_aud_iis_da0";
		};

		clk@402d0270 {
			compatible = "sprd,gates-clock";
			#clock-cells = <0x01>;
			reg = <0x00 0x402d0270 0x00 0x04>;
			sprd,gates-msk = <0x10000>;
			clocks = <0x8b>;
			clock-output-names = "clk_aud_iis_ad0";
		};

		clk@402d0274 {
			compatible = "sprd,muxed-clock";
			#clock-cells = <0x00>;
			reg = <0x00 0x402d0274 0x00 0x04>;
			sprd,mux-msk = <0x03>;
			clocks = <0x05 0x0a 0x31 0x56>;
			clock-output-names = "clk_ca53_dap";
		};

		clk@402d0278 {
			compatible = "sprd,gates-clock";
			#clock-cells = <0x01>;
			reg = <0x00 0x402d0278 0x00 0x04>;
			sprd,gates-msk = <0x10000>;
			clocks = <0x8b>;
			clock-output-names = "clk_ca53_dmtck";
		};

		clk@402d027c {
			compatible = "sprd,muxed-clock";
			#clock-cells = <0x00>;
			reg = <0x00 0x402d027c 0x00 0x04>;
			sprd,mux-msk = <0x03>;
			clocks = <0x95 0x05 0x31 0x56>;
			clock-output-names = "clk_ca53_ts";
		};

		clk@402d0280 {
			compatible = "sprd,gates-clock";
			#clock-cells = <0x01>;
			reg = <0x00 0x402d0280 0x00 0x04>;
			sprd,gates-msk = <0x10000>;
			clocks = <0x8b>;
			clock-output-names = "clk_djtag_tck";
		};

		clk@402d028c {
			compatible = "sprd,muxed-clock";
			#clock-cells = <0x00>;
			reg = <0x00 0x402d028c 0x00 0x04>;
			sprd,mux-msk = <0x03>;
			clocks = <0x98 0x99 0x05>;
			clock-output-names = "clk_";
		};

		clk@402d0290 {
			compatible = "sprd,composite-clock";
			#clock-cells = <0x00>;
			reg = <0x00 0x402d0290 0x00 0x04>;
			sprd,mux-msk = <0x07>;
			sprd,div-msk = <0x300>;
			clocks = <0x05 0x09 0x31 0x56 0x58>;
			clock-output-names = "clk_cssys";
			linux,phandle = <0x67>;
			phandle = <0x67>;
		};

		clk@402d0298 {
			compatible = "sprd,muxed-clock";
			#clock-cells = <0x00>;
			reg = <0x00 0x402d0298 0x00 0x04>;
			sprd,mux-msk = <0x01>;
			clocks = <0x95 0x9a>;
			clock-output-names = "clk_tmr";
		};

		clk@402d02a0 {
			compatible = "sprd,gates-clock";
			#clock-cells = <0x01>;
			reg = <0x00 0x402d02a0 0x00 0x04>;
			sprd,gates-msk = <0x10000>;
			clocks = <0x8b>;
			clock-output-names = "clk_dsi_test";
		};

		clk@402d02b8 {
			compatible = "sprd,muxed-clock";
			#clock-cells = <0x00>;
			reg = <0x00 0x402d02b8 0x00 0x04>;
			sprd,mux-msk = <0x01>;
			clocks = <0x05 0x0b>;
			clock-output-names = "clk_sdphy_apb";
		};

		clk@402d02c4 {
			compatible = "sprd,composite-clock";
			#clock-cells = <0x00>;
			reg = <0x00 0x402d02c4 0x00 0x04>;
			sprd,mux-msk = <0x01>;
			sprd,div-msk = <0x300>;
			clocks = <0x05 0x0b>;
			clock-output-names = "clk_aio_apb";
		};

		clk@402d02c8 {
			compatible = "sprd,gates-clock";
			#clock-cells = <0x01>;
			reg = <0x00 0x402d02c8 0x00 0x04>;
			sprd,gates-msk = <0x10000>;
			clocks = <0x8b>;
			clock-output-names = "clk_dtck_hw";
		};

		clk@402d02cc {
			compatible = "sprd,composite-clock";
			#clock-cells = <0x00>;
			reg = <0x00 0x402d02cc 0x00 0x04>;
			sprd,mux-msk = <0x03>;
			sprd,div-msk = <0x300>;
			clocks = <0x05 0x09 0x31>;
			clock-output-names = "clk_ap_mm";
		};

		clk@402d02d0 {
			compatible = "sprd,muxed-clock";
			#clock-cells = <0x00>;
			reg = <0x00 0x402d02d0 0x00 0x04>;
			sprd,mux-msk = <0x03>;
			clocks = <0x05 0x0a 0x31 0x58>;
			clock-output-names = "clk_ap_axi";
			linux,phandle = <0x84>;
			phandle = <0x84>;
		};

		clk@402d02d8 {
			compatible = "sprd,composite-clock";
			#clock-cells = <0x00>;
			reg = <0x00 0x402d02d8 0x00 0x04>;
			sprd,mux-msk = <0x07>;
			sprd,div-msk = <0x700>;
			clocks = <0x58 0x59 0x2d 0x85 0x9b>;
			clock-output-names = "clk_nic_gpu";
		};

		clk@402d02dc {
			compatible = "sprd,muxed-clock";
			#clock-cells = <0x00>;
			reg = <0x00 0x402d02dc 0x00 0x04>;
			sprd,mux-msk = <0x07>;
			clocks = <0x31 0x58 0x59 0x2d 0x5c>;
			clock-output-names = "clk_mm_isp";
			linux,phandle = <0x5b>;
			phandle = <0x5b>;
		};

		clk@402e0000 {
			compatible = "sprd,sc1000-gates-clock";
			#clock-cells = <0x01>;
			reg = <0x00 0x402e0000 0x00 0x3000>;
			sprd,gates-msk = <0x9f7fffff>;
			clocks = <0x9c>;
			clock-output-names = "adc_eb\0fm_eb\0tpc_eb\0gpio_eb\0pwm0_eb\0pwm1_eb\0pwm2_eb\0pwm3_eb\0kpd_eb\0aon_syst_eb\0ap_syst_eb\0aon_tmr_eb\0ap_tmr0_eb\0efuse_eb\0eic_eb\0intc_eb\0adi_eb\0audif_eb\0aud_eb\0vbc_eb\0pin_eb\0ipi_eb\0splk_eb\0ap_wdg_eb\0mm_eb\0aon_apb_ckg_eb\0gpu_eb\0ca7_ts0_eb\0ca7_dap_eb";
			linux,phandle = <0x3a>;
			phandle = <0x3a>;
		};

		clk@402e0004 {
			compatible = "sprd,sc1000-gates-clock";
			#clock-cells = <0x01>;
			reg = <0x00 0x402e0004 0x00 0x3000>;
			sprd,gates-msk = <0xf97e7fbf>;
			clocks = <0x9c>;
			clock-output-names = "pmu_eb\0thm0_eb\0aux0_eb\0aux1_eb\0aux2_eb\0probe_eb\0clk_emc_ref_eb\0ca53_wdg_eb\0ap_tmr1_eb\0ap_tmr2_eb\0disp_emc_eb\0zip_emc_eb\0gsp_emc_eb\0mm_vsp_eb\0mdar_eb\0aon_intc_eb\0thm1_eb\0djtag_eb\0mbox_eb\0aon_dma_eb\0lvds_pll_div_en\0orp_jtag_eb\0dbg_eb\0dbg_emc_eb\0cross_trig_eb\0serdes_dphy_eb";
			linux,phandle = <0x48>;
			phandle = <0x48>;
		};

		clk@402e0010 {
			compatible = "sprd,sc1000-gates-clock";
			#clock-cells = <0x01>;
			reg = <0x00 0x402e0010 0x00 0x3000>;
			sprd,gates-msk = <0x7ffff>;
			clocks = <0x9c>;
			clock-output-names = "arch_rtc_eb\0kpb_rtc_eb\0aon_syst_rtc_eb\0ap_syst_rtc_eb\0aon_tmr_rtc_eb\0ap_tmr0_rtc_eb\0eic_rtc_eb\0eic_rtcdv5_eb\0ap_wdg_rtc_eb\0ca53_wdg_rtc_eb\0thm_rtc_eb\0athma_rtc_eb\0gthma_rtc_eb\0athma_rtc_a_en\0gthma_rtc_a_en\0ap_trm1_rtc_eb\0ap_tmr2_rtc_eb\0dxco_lc_rtc_eb\0bb_cal_rtc_eb";
			linux,phandle = <0x4b>;
			phandle = <0x4b>;
		};

		clk@402e00b0 {
			compatible = "sprd,sc1000-gates-clock";
			#clock-cells = <0x01>;
			reg = <0x00 0x402e00b0 0x00 0x3000>;
			sprd,gates-msk = <0x1ffb0>;
			clocks = <0x9c>;
			clock-output-names = "cssys_eb\0dmc_eb\0rosc_eb\0s_d_cfg_eb\0s_d_ref_eb\0b_dma_eb\0anlg_eb\0pin_apb_eb\0anlg_apb_eb\0bsmtmr_eb\0ap_dap_eb\0apsim_aontop_eb";
		};

		clk@0402e0134 {
			compatible = "sprd,sc1000-gates-clock";
			#clock-cells = <0x01>;
			reg = <0x00 0x402e0134 0x00 0x3000>;
			sprd,gates-msk = <0x40f01>;
			clocks = <0x9c>;
			clock-output-names = "tsen_eb\0cssys_ca53_eb\0ap_hs_spi_eb\0det_32k_eb\0tmr_eb\0apll_test_eb";
			linux,phandle = <0x1d>;
			phandle = <0x1d>;
		};

		clk@60100004 {
			compatible = "sprd,composite-clock";
			#clock-cells = <0x00>;
			reg = <0x00 0x60100004 0x00 0x04>;
			sprd,mux-msk = <0x07>;
			sprd,div-msk = <0x70>;
			clocks = <0x58 0x59 0x2d 0x85 0x9b>;
			clock-output-names = "clk_gpu";
			linux,phandle = <0xa1>;
			phandle = <0xa1>;
		};

		clk@60d00000 {
			compatible = "sprd,gates-clock";
			#clock-cells = <0x01>;
			reg = <0x00 0x60d00000 0x00 0x04>;
			sprd,gates-msk = <0x7f>;
			clocks = <0x55>;
			clock-output-names = "dcam_eb\0isp_eb\0cpp_eb\0csi_eb\0csi_s_eb\0jpg_eb\0mahb_ckg_eb";
			linux,phandle = <0x54>;
			phandle = <0x54>;
		};

		clk@60d00008 {
			compatible = "sprd,gates-clock";
			#clock-cells = <0x01>;
			reg = <0x00 0x60d00008 0x00 0x04>;
			sprd,gates-msk = <0x3f>;
			clocks = <0x55>;
			clock-output-names = "cphy_cfg_ckg_en\0sensor0_ckg_en\0sensor1_ckg_en\0isp_axi_ckg_en\0mcsi_ckg_en\0mcsi_s_ckg_en";
			linux,phandle = <0x08>;
			phandle = <0x08>;
		};

		clk@60e00020 {
			compatible = "sprd,muxed-clock";
			#clock-cells = <0x00>;
			reg = <0x00 0x60e00020 0x00 0x04>;
			sprd,mux-msk = <0x03>;
			clocks = <0x05 0x09 0x31 0x56>;
			clock-output-names = "clk_mm_ahb";
			linux,phandle = <0x55>;
			phandle = <0x55>;
		};

		clk@60e00024 {
			compatible = "sprd,composite-clock";
			#clock-cells = <0x00>;
			reg = <0x00 0x60e00024 0x00 0x04>;
			sprd,mux-msk = <0x03>;
			sprd,div-msk = <0x700>;
			clocks = <0x05 0x0b 0x0a 0x09>;
			clock-output-names = "clk_sensor0";
			linux,phandle = <0x07>;
			phandle = <0x07>;
		};

		clk@60e00028 {
			compatible = "sprd,composite-clock";
			#clock-cells = <0x00>;
			reg = <0x00 0x60e00028 0x00 0x04>;
			sprd,mux-msk = <0x03>;
			sprd,div-msk = <0x700>;
			clocks = <0x05 0x0b 0x0a 0x09>;
			clock-output-names = "clk_sensor1";
			linux,phandle = <0x12>;
			phandle = <0x12>;
		};

		clk@60e0002c {
			compatible = "sprd,muxed-clock";
			#clock-cells = <0x00>;
			reg = <0x00 0x60e0002c 0x00 0x04>;
			sprd,mux-msk = <0x03>;
			clocks = <0x0a 0x56 0x58 0x59>;
			clock-output-names = "clk_dcam_if";
			linux,phandle = <0x57>;
			phandle = <0x57>;
		};

		clk@60e00030 {
			compatible = "sprd,muxed-clock";
			#clock-cells = <0x00>;
			reg = <0x00 0x60e00030 0x00 0x04>;
			sprd,mux-msk = <0x03>;
			clocks = <0x0a 0x31 0x58 0x59>;
			clock-output-names = "clk_jpg";
			linux,phandle = <0x5e>;
			phandle = <0x5e>;
		};

		clk@60e00034 {
			compatible = "sprd,gates-clock";
			#clock-cells = <0x01>;
			reg = <0x00 0x60e00034 0x00 0x04>;
			sprd,gates-msk = <0x10000>;
			clocks = <0x55>;
			clock-output-names = "clk_mipi_csi";
			linux,phandle = <0x5f>;
			phandle = <0x5f>;
		};

		clk@60e0003c {
			compatible = "sprd,gates-clock";
			#clock-cells = <0x01>;
			reg = <0x00 0x60e0003c 0x00 0x04>;
			sprd,gates-msk = <0x10000>;
			clocks = <0x55>;
			clock-output-names = "clk_mcsi_s";
			linux,phandle = <0x61>;
			phandle = <0x61>;
		};

		clk@71300000 {
			compatible = "sprd,sc1000-gates-clock";
			#clock-cells = <0x01>;
			reg = <0x00 0x71300000 0x00 0x3000>;
			sprd,gates-msk = <0x7c5fa7>;
			clocks = <0x8b>;
			clock-output-names = "sim0_eb\0iis0_eb\0apb_reg_eb\0spi0_eb\0spi2_eb\0i2c0_eb\0i2c1_eb\0i2c2_eb\0i2c3_eb\0i2c4_eb\0uart1_eb\0sim0_32k_eb\0intc0_eb\0intc1_eb\0intc2_eb\0intc3_eb";
			linux,phandle = <0x03>;
			phandle = <0x03>;
		};
	};

	sprd-pcm-audio {
		compatible = "sprd,pcm-platform-sharkl2";
		#sound-dai-cells = <0x00>;
		dmas = <0x9d 0x01 0x9d 0x02 0x9d 0x03 0x9d 0x04 0x9d 0x05 0x9d 0x06 0x9d 0x07 0x9d 0x08 0x1a 0x01 0x1a 0x02>;
		dma-names = "da01-l\0da01-r\0da23-l\0da23-r\0normal-2stage-p\0normal-2stage-c\0deep-2stage-p\0ad23-2stage-c\0ad01-l\0ad01-r";
		sprd,dma-2stage-usecase = <0x02>;
		sprd,node-count-2stage-level-1 = <0x01>;
		sprd,syscon-pmu-apb = <0x3c>;
		sprd,dma-2stage-level-1-int-source = <0x01>;
		sprd,dma_use_ddr_reserved = <0x01>;
		memory-region = <0x9e>;
		linux,phandle = <0xba>;
		phandle = <0xba>;
	};

	vaudio {
		compatible = "sprd,vaudio";
		#sound-dai-cells = <0x01>;
		clocks = <0x9f 0x08>;
		clock-names = "tuned_26m";
		linux,phandle = <0xbd>;
		phandle = <0xbd>;
	};

	sprd-pcm-iis {
		compatible = "sprd,pcm-platform-sharkl2";
		#sound-dai-cells = <0x00>;
		dmas = <0x1a 0x05 0x1a 0x06>;
		dma-names = "iis0_tx\0iis0_rx";
		sprd,dma-2stage-usecase = <0x02>;
		sprd,node-count-2stage-level-1 = <0x01>;
		sprd,syscon-pmu-apb = <0x3c>;
		sprd,dma-2stage-level-1-int-source = <0x01>;
		sprd,dma_use_ddr_reserved = <0x01>;
		memory-region = <0x9e>;
		linux,phandle = <0xbe>;
		phandle = <0xbe>;
	};

	saudio_lte {
		compatible = "sprd,saudio";
		sprd,saudio-dst-id = <0x05>;
		sprd,ctrl_channel = <0x0a>;
		sprd,playback_channel = <0x0b 0x83>;
		sprd,capture_channel = <0x0c>;
		sprd,monitor_channel = <0x0d>;
		sprd,device = <0x02>;
		sprd,saudio-names = "saudiolte";
	};

	saudio_voip {
		compatible = "sprd,saudio";
		sprd,saudio-dst-id = <0x05>;
		sprd,ctrl_channel = <0x0e>;
		sprd,playback_channel = <0x0f 0x97>;
		sprd,capture_channel = <0x10>;
		sprd,monitor_channel = <0x11>;
		sprd,device = <0x02>;
		sprd,saudio-names = "saudiovoip";
	};

	audio-mem-mgr {
		compatible = "sprd,audio-mem-sharkl2";
		sprd,iram_phy_addr = <0x3400 0xb000>;
		sprd,iram_normal = <0x3400 0x00>;
		sprd,iram_deepbuf = <0x3400 0xa000>;
		sprd,iram_4arm7 = <0xd400 0x1000>;
	};

	gpu@60000000 {
		compatible = "sprd,mali-midgard";
		reg = <0x00 0x60000000 0x00 0x4000>;
		gpu-supply = <0xa0>;
		syscons = <0x3c 0x20 0x2000000>;
		syscon-names = "top_force_shutdown";
		sprd,syscon-aon-apb = <0x2e>;
		sprd,syscon-pmu-apb = <0x3c>;
		interrupts = <0x00 0x27 0x04 0x00 0x27 0x04 0x00 0x27 0x04>;
		interrupt-names = "JOB\0MMU\0GPU";
		system-coherency = <0x1f>;
		clocks = <0x3a 0x1b 0xa1 0x58 0x59 0x2d 0x85 0x9b>;
		operating-points = <0x3e800 0xdbba0 0x5dc00 0xdbba0 0x7d000 0xdbba0 0x927c0 0xdbba0 0xa6040 0xe7ef0>;
		sprd,dfs-lists = <0x3e800 0xdbba0 0x02 0x01 0x5dc00 0xdbba0 0x04 0x01 0x7d000 0xdbba0 0x05 0x01 0x927c0 0xdbba0 0x06 0x01 0xa6040 0xe7ef0 0x06 0x01>;
		sprd,dfs-default = <0x01>;
		sprd,dfs-scene-extreme = <0x03>;
		sprd,dfs-scene-high = <0x02>;
		sprd,dfs-scene-medium = <0x01>;
		sprd,dfs-scene-low = <0x00>;
		sprd,dfs-range-max = <0x03>;
		sprd,dfs-range-min = <0x00>;
	};

	clk26mhz {
		compatible = "fixed-clock";
		#clock-cells = <0x00>;
		clock-frequency = <0x18cba80>;
	};

	clk-default {
		compatible = "sprd,clk-default";
		sprd,syscon-pmu-apb = <0x3c>;
		sprd,syscon-aon-apb = <0x2e>;
		pmu-pwd-list = <0x1c 0x3000000 0x2000000 0x20 0x3000000 0x2000000>;
		clock-names = "clk_gpu_eb\0clk_mm_eb";
		clocks = <0x3a 0x1b 0x3a 0x19>;
	};

	cpus {
		#address-cells = <0x02>;
		#size-cells = <0x00>;

		cpu-map {

			cluster0 {

				core0 {
					cpu = <0x70>;
				};

				core1 {
					cpu = <0x72>;
				};

				core2 {
					cpu = <0x74>;
				};

				core3 {
					cpu = <0x76>;
				};
			};
		};

		cpu@000000 {
			device_type = "cpu";
			compatible = "arm,cortex-a53\0arm,armv8";
			reg = <0x00 0x00>;
			enable-method = "psci";
			cpu-idle-states = <0xa2 0xa3>;
			cpu-supply = <0xa4>;
			cpufreq-data-v1 = <0xa5>;
			linux,phandle = <0x70>;
			phandle = <0x70>;
		};

		cpu@000001 {
			device_type = "cpu";
			compatible = "arm,cortex-a53\0arm,armv8";
			reg = <0x00 0x01>;
			enable-method = "psci";
			cpu-idle-states = <0xa2 0xa3>;
			cpu-supply = <0xa4>;
			cpufreq-data-v1 = <0xa5>;
			linux,phandle = <0x72>;
			phandle = <0x72>;
		};

		cpu@000002 {
			device_type = "cpu";
			compatible = "arm,cortex-a53\0arm,armv8";
			reg = <0x00 0x02>;
			enable-method = "psci";
			cpu-idle-states = <0xa2 0xa3>;
			cpu-supply = <0xa4>;
			cpufreq-data-v1 = <0xa5>;
			linux,phandle = <0x74>;
			phandle = <0x74>;
		};

		cpu@000003 {
			device_type = "cpu";
			compatible = "arm,cortex-a53\0arm,armv8";
			reg = <0x00 0x03>;
			enable-method = "psci";
			cpu-idle-states = <0xa2 0xa3>;
			cpu-supply = <0xa4>;
			cpufreq-data-v1 = <0xa5>;
			linux,phandle = <0x76>;
			phandle = <0x76>;
		};
	};

	cpufreq-clus0 {
		clocks = <0x87 0x86 0x7d>;
		clock-names = "core_clk\0low_freq_clk_parent\0high_freq_clk_parent";
		clock-latency = <0xc350>;
		voltage-tolerance = <0x00>;
		sprd,efuse-blk-binning-low-volt = <0x27 0x20000000>;
		sprd,efuse-blk-binning = <0x27 0xf00>;
		sprd,cpufreq-temp-threshold = <0x41>;
		sprd,ss-waferid-names = "T8F619_1\0T8F619_2\0T8F619_3\0T8F619_4\0T8F619_6\0T8F619_7\0T8F619_8\0T8F619_10\0T8F619_11\0T8F619_12\0T8F619_13\0T8F619_15\0T8F619_16\0T8F619_18\0T8F619_19\0T8F619_20\0T8F619_22\0T8F619_23\0T8F619_24\0T8F619_25\0T8F622_1\0T8F622_2\0T8F622_3\0T8F622_4\0T8F622_5\0T8F622_6\0T8F801_1\0T8F801_2\0T8F801_4\0T8F801_3\0T9S964_1";
operating-points = <
	/* kHz  uV */
	1820000 1354375
	1700000 1275000
	1600000 1225000
	1500000 1175000
	1400000 1125000
	1300000 1100000
	1100000 1000000
	 900000  900000
	 768000  900000>;
operating-points-1-0 = <
	/* kHz	uV */
	1820000 1290625
	1700000 1206250
	1600000 1162500
	1500000 1056250
	1400000 1021875
	1300000  987500
	1100000  918750
	 900000  900000
	 768000  900000>;
operating-points-2-0 = <
	/* kHz	uV */
	1820000 1328125
	1700000 1243750
	1600000 1200000
	1500000 1109375
	1400000 1071875
	1300000 1034375
	1100000  959375
	 900000  900000
	 768000  900000>;
operating-points-3-0 = <
	/* kHz	uV */
	1820000 1340625
	1700000 1262500
	1600000 1218750
	1500000 1175000
	1400000 1121875
	1300000 1081250
	1100000 1000000
	 900000  921875
	 768000  900000>;
operating-points-4-0 = <
	/* kHz	uV */
	1820000 1354375
	1700000 1281250
	1600000 1243750
	1500000 1200000
	1400000 1150000
	1300000 1112500
	1100000 1034375
	 900000  953125
	 768000  900000>;
operating-points-1-1 = <
	/* kHz	uV */
	1820000 1290625
	1700000 1206250
	1600000 1162500
	1500000 1056250
	1400000 1021875
	1300000  987500
	1100000  918750
	 900000  850000
	 768000  850000>;
operating-points-2-1 = <
	/* kHz	uV */
	1820000 1328125
	1700000 1243750
	1600000 1200000
	1500000 1109375
	1400000 1071875
	1300000 1034375
	1100000  959375
	 900000  881250
	 768000  850000>;
operating-points-3-1 = <
	/* kHz	uV */
	1820000 1340625
	1700000 1262500
	1600000 1218750
	1500000 1175000
	1400000 1121875
	1300000 1081250
	1100000 1000000
	 900000  921875
	 768000  868750>;
operating-points-4-1 = <
	/* kHz	uV */
	1820000 1354375
	1700000 1281250
	1600000 1243750
	1500000 1200000
	1400000 1150000
	1300000 1112500
	1100000 1034375
	 900000  953125
	 768000  900000>;
operating-points-1-0-65 = <
	/* kHz	uV */
	1820000 1309375
	1700000 1225000
	1600000 1181250
	1500000 1084375
	1400000 1043750
	1300000 1003125
	1100000  921875
	 900000  900000
	 768000  900000>;
operating-points-2-0-65 = <
	/* kHz	uV */
	1820000 1346875
	1700000 1262500
	1600000 1218750
	1500000 1140625
	1400000 1096875
	1300000 1053125
	1100000  965625
	 900000  900000
	 768000  900000>;
operating-points-3-0-65 = <
	/* kHz	uV */
	1820000 1354375
	1700000 1287500
	1600000 1243750
	1500000 1200000
	1400000 1150000
	1300000 1106250
	1100000 1015625
	 900000  925000
	 768000  900000>;
operating-points-4-0-65 = <
	/* kHz	uV */
	1820000 1354375
	1700000 1300000
	1600000 1262500
	1500000 1218750
	1400000 1181250
	1300000 1137500
	1100000 1050000
	 900000  959375
	 768000  900000>;
operating-points-1-1-65 = <
	/* kHz	uV */
	1820000 1309375
	1700000 1225000
	1600000 1181250
	1500000 1084375
	1400000 1043750
	1300000 1003125
	1100000  921875
	 900000  900000
	 768000  900000>;
operating-points-2-1-65 = <
	/* kHz	uV */
	1820000 1346875
	1700000 1262500
	1600000 1218750
	1500000 1140625
	1400000 1096875
	1300000 1053125
	1100000  965625
	 900000  900000
	 768000  900000>;
operating-points-3-1-65 = <
	/* kHz	uV */
	1820000 1354375
	1700000 1287500
	1600000 1243750
	1500000 1200000
	1400000 1150000
	1300000 1106250
	1100000 1015625
	 900000  925000
	 768000  900000>;
operating-points-4-1-65 = <
	/* kHz	uV */
	1820000 1354375
	1700000 1300000
	1600000 1262500
	1500000 1218750
	1400000 1181250
	1300000 1137500
	1100000 1050000
	 900000  959375
	 768000  900000>;
operating-points-3 = <
	/* kHz	uV */
	1820000 1340625
	1700000 1262500
	1600000 1218750
	1500000 1175000
	1400000 1121875
	1300000 1081250
	1100000 1000000
	 900000  921875
	 768000  900000>;
operating-points-4 = <
	/* kHz	uV */
	1820000 1354375
	1700000 1281250
	1600000 1243750
	1500000 1200000
	1400000 1150000
	1300000 1112500
	1100000 1034375
	 900000  953125
	 768000  900000>;
operating-points-3-65 = <
	/* kHz	uV */
	1820000 1354375
	1700000 1287500
	1600000 1243750
	1500000 1200000
	1400000 1150000
	1300000 1106250
	1100000 1015625
	 900000  925000
	 768000  900000>;
operating-points-4-65 = <
	/* kHz	uV */
	1820000 1354375
	1700000 1300000
	1600000 1262500
	1500000 1218750
	1400000 1181250
	1300000 1137500
	1100000 1050000
	 900000  959375
	 768000  900000>;
		linux,phandle = <0xa5>;
		phandle = <0xa5>;
	};

	idle-states {
		entry-method = "arm,psci";

		core_pd {
			compatible = "arm,idle-state";
			entry-latency-us = <0x3e8>;
			exit-latency-us = <0x1f4>;
			min-residency-us = <0x9c4>;
			local-timer-stop;
			arm,psci-suspend-param = <0x10000>;
			linux,phandle = <0xa2>;
			phandle = <0xa2>;
		};

		cluster_pd {
			compatible = "arm,idle-state";
			entry-latency-us = <0xffffffff>;
			exit-latency-us = <0xffffffff>;
			min-residency-us = <0xffffffff>;
			local-timer-stop;
			arm,psci-suspend-param = <0x1010000>;
			linux,phandle = <0xa3>;
			phandle = <0xa3>;
		};
	};

	psci {
		compatible = "arm,psci-1.0";
		method = "smc";
	};

	interrupt-controller@12001000 {
		compatible = "arm,gic-400";
		reg = <0x00 0x12001000 0x00 0x1000 0x00 0x12002000 0x00 0x2000 0x00 0x12004000 0x00 0x2000 0x00 0x12006000 0x00 0x2000>;
		#interrupt-cells = <0x03>;
		interrupt-controller;
		interrupts = <0x01 0x09 0xf04>;
		linux,phandle = <0x01>;
		phandle = <0x01>;
	};

	timer {
		compatible = "arm,armv8-timer";
		interrupts = <0x01 0x0e 0xf08 0x01 0x0a 0xf08>;
		clock-frequency = <0x18cba80>;
	};

	pmu {
		compatible = "arm,cortex-a53-pmu";
		interrupts = <0x00 0x5c 0x04 0x00 0x5d 0x04 0x00 0x5e 0x04 0x00 0x5f 0x04>;
	};

	sprd-gsp {
		compatible = "sprd,gsp-lite_r2p0-sharkle";
		core-cnt = <0x01>;
		io-cnt = <0x07>;
		cores = <0xa6>;
	};

	deep-sleep {
		compatible = "sprd,deep-sleep";
		sprd,sys-ap-ahb = <0x21>;
		sprd,sys-ap-apb = <0x20>;
		sprd,sys-pmu-apb = <0x3c>;
		sprd,sys-aon-apb = <0x2e>;
		sprd,sys-ap-intc0 = <0xa7>;
		sprd,sys-ap-intc1 = <0xa8>;
		sprd,sys-ap-intc2 = <0xa9>;
		sprd,sys-ap-intc3 = <0xaa>;
		sprd,sys-aon-intc = <0xab>;
		sprd,deep-ap-clk0 = <0x8b 0xac 0x04 0x06 0x14 0x16 0x17 0x18 0x1b 0x1f 0x1e 0xad 0xae 0x26 0xaf 0x23>;
		sprd,deep-ap-clk1 = <0xb0 0x2c 0x32>;
		sprd,deep-ap-clk2 = <0xb1>;
		sprd,deep-ap-clk3 = <0x51>;
		sprd,deep-ap-clkp = <0x05 0x89 0x56 0x0a>;
		clocks = <0x8b 0xac 0x04 0x06 0x14 0x16 0x17 0x18 0x1b 0x1f 0x1e 0xad 0xae 0x26 0xaf 0x23 0xb0 0x2c 0x32 0xb1 0x51 0x05 0x89 0x56 0x0a>;
	};

	sprd-hotplug {
		enable-dynamic-hotplug;
	};

	mailbox@400a0000 {
		compatible = "sprd,mailbox";
		reg = <0x00 0x400a0000 0x00 0x8000 0x00 0x400a8000 0x00 0x8000>;
		sprd,syscon-ap-apb = <0x2e>;
		interrupts = <0x00 0x44 0x00 0x00 0x45 0x00>;
		sprd,core-cnt = <0x07>;
		sprd,version = <0x03>;
	};

	scproc@50800000 {
		compatible = "sprd,scproc_pubcp";
		sprd,name = "pmic";
		sprd,syscon-ap-apb = <0x2e>;
		sprd,syscon-ap-pmu = <0x3c>;
		sprd,ctrl-reg = <0xff 0xff 0x114 0xff 0xff>;
		sprd,ctrl-mask = <0x00 0x200000 0x01 0x00 0x00>;
		sprd,ctrl-type = <0x00 0x01 0x00 0x00 0x00>;
		reg = <0x00 0x50800000 0x00 0xe400>;
		#address-cells = <0x01>;
		#size-cells = <0x01>;
		ranges = <0x00 0x00 0x50800000 0xe400>;

		pm_sys@0 {
			cproc,name = "pm_sys";
			reg = <0x00 0xe400>;
		};
	};

	sipc@0xe400 {
		compatible = "sprd,sipc-v1";
		sprd,name = "sipc-pmsys";
		sprd,dst = <0x06 0x01>;
		sprd,smem-info = <0xe400 0x2000e400 0x800>;
	};

	scproc@10000 {
		compatible = "sprd,scproc_pubcp";
		sprd,decoup = "cproc-use-decoup";
		sprd,name = "cptl";
		sprd,syscon-ap-apb = <0x2e>;
		sprd,syscon-ap-pmu = <0x3c>;
		sprd,ctrl-reg = <0x48 0xcc 0x284 0xb0 0xff>;
		sprd,ctrl-mask = <0x2000000 0x40000 0x400 0x02 0x00>;
		sprd,ctrl-type = <0x01 0x01 0x00 0x01 0x00>;
		reg = <0x00 0x10000 0x00 0x1000>;
	};

	sipc@87800000 {
		compatible = "sprd,sipc-v1";
		sprd,name = "sipc-lte";
		sprd,dst = <0x05 0x02>;
		sprd,smem-info = <0x87800000 0x87800000 0x3d0000>;
	};

	slog-pm {
		compatible = "sprd,spipe";
		sprd,name = "slog_pm";
		sprd,dst = <0x06>;
		sprd,channel = <0x05>;
		sprd,ringnr = <0x01>;
		sprd,size-rxbuf = <0x5b0>;
		sprd,size-txbuf = <0x100>;
	};

	sctl-pm {
		compatible = "sprd,spipe";
		sprd,name = "sctl_pm";
		sprd,dst = <0x06>;
		sprd,channel = <0x06>;
		sprd,ringnr = <0x01>;
		sprd,size-rxbuf = <0xc0>;
		sprd,size-txbuf = <0x40>;
	};

	spipe-lte {
		compatible = "sprd,spipe";
		sprd,name = "spipe_lte";
		sprd,dst = <0x05>;
		sprd,channel = <0x04>;
		sprd,ringnr = <0x0f>;
		sprd,size-rxbuf = <0x1000>;
		sprd,size-txbuf = <0x1000>;
	};

	slog-lte {
		compatible = "sprd,spool";
		sprd,name = "slog_lte";
		sprd,dst = <0x05>;
		sprd,channel = <0x05>;
		sprd,tx-blksize = <0x00>;
		sprd,tx-blknum = <0x00>;
		sprd,rx-blksize = <0x10000>;
		sprd,rx-blknum = <0x04>;
	};

	sdiag-lte {
		compatible = "sprd,spipe";
		sprd,name = "sdiag_lte";
		sprd,dst = <0x05>;
		sprd,channel = <0x15>;
		sprd,ringnr = <0x01>;
		sprd,size-rxbuf = <0x40000>;
		sprd,size-txbuf = <0x8000>;
	};

	stty-lte {
		compatible = "sprd,spipe";
		sprd,name = "stty_lte";
		sprd,dst = <0x05>;
		sprd,channel = <0x06>;
		sprd,ringnr = <0x20>;
		sprd,size-rxbuf = <0x800>;
		sprd,size-txbuf = <0x800>;
	};

	sipx-lte {
		compatible = "sprd,sipx";
		sprd,name = "sipx_lte";
		sprd,dst = <0x05>;
		sprd,dl-pool = <0x200>;
		sprd,dl-ack-pool = <0x40>;
		sprd,ul-pool = <0x400>;
		sprd,ul-ack-pool = <0x400>;
	};

	seth0-lte {
		compatible = "sprd,seth";
		sprd,name = "seth_lte0";
		sprd,dst = <0x05>;
		sprd,channel = <0x07>;
		sprd,blknum = <0x100>;
		sprd,poolsize = <0x10>;
	};

	seth1-lte {
		compatible = "sprd,seth";
		sprd,name = "seth_lte1";
		sprd,dst = <0x05>;
		sprd,channel = <0x08>;
		sprd,blknum = <0x100>;
		sprd,poolsize = <0x10>;
	};

	seth2-lte {
		compatible = "sprd,seth";
		sprd,name = "seth_lte2";
		sprd,dst = <0x05>;
		sprd,channel = <0x09>;
		sprd,blknum = <0x100>;
		sprd,poolsize = <0x10>;
	};

	seth3-lte {
		compatible = "sprd,seth";
		sprd,name = "seth_lte3";
		sprd,dst = <0x05>;
		sprd,channel = <0x12>;
		sprd,blknum = <0x100>;
		sprd,poolsize = <0x10>;
	};

	seth4-lte {
		compatible = "sprd,seth";
		sprd,name = "seth_lte4";
		sprd,dst = <0x05>;
		sprd,channel = <0x13>;
		sprd,blknum = <0x100>;
		sprd,poolsize = <0x10>;
	};

	seth5-lte {
		compatible = "sprd,seth";
		sprd,name = "seth_lte5";
		sprd,dst = <0x05>;
		sprd,channel = <0x14>;
		sprd,blknum = <0x100>;
		sprd,poolsize = <0x10>;
	};

	seth6-lte {
		compatible = "sprd,seth";
		sprd,name = "seth_lte6";
		sprd,dst = <0x05>;
		sprd,channel = <0x18>;
		sprd,blknum = <0x100>;
		sprd,poolsize = <0x10>;
	};

	seth7-lte {
		compatible = "sprd,seth";
		sprd,name = "seth_lte7";
		sprd,dst = <0x05>;
		sprd,channel = <0x19>;
		sprd,blknum = <0x100>;
		sprd,poolsize = <0x10>;
	};

	cpwcn_btwf {
		compatible = "sprd,integrate_marlin";
		sprd,name = "wcn_btwf";
		sprd,syscon-ap-apb = <0x2e>;
		sprd,syscon-ap-pmu = <0x3c>;
		sprd,syscon-ap-pub-apb = <0xb2>;
		sprd,syscon-anlg-wrap-wcn = <0xb3>;
		sprd,syscon-anlg-phy-g6 = <0x3b>;
		sprd,ctrl-probe-num = <0x02>;
		sprd,ctrl-reg = <0x1578 0x30a0 0x2100 0x20cc 0x20b0 0x157c>;
		sprd,ctrl-mask = <0x3000000 0xffff 0x3000000 0x80000 0x600 0x80>;
		sprd,ctrl-value = <0x00 0x808 0x3000000 0x80000 0x600 0x80>;
		sprd,ctrl-rw-offset = <0x1000 0x00 0x2000 0x2000 0x2000 0x1000>;
		sprd,ctrl-us-delay = <0x0a 0x0a 0x0a 0x0a 0x0a 0x0a>;
		sprd,ctrl-type = <0x00 0x02 0x01 0x01 0x01 0x00>;
		sprd,ctrl-shutdown-reg = <0x257c 0x10b0>;
		sprd,ctrl-shutdown-mask = <0x80 0x400>;
		sprd,ctrl-shutdown-value = <0x80 0x400>;
		sprd,ctrl-shutdown-rw-offset = <0x2000 0x1000>;
		sprd,ctrl-shutdown-us-delay = <0x0a 0x0a>;
		sprd,ctrl-shutdown-type = <0x00 0x01>;
		reg = <0x00 0x88000000 0x00 0x180000>;
		sprd,file-length = <0x178000>;
		memory_region = <0xb4>;
		vddwcn-supply = <0xb5>;
		vddwifipa-supply = <0xb6>;
		#address-cells = <0x01>;
		#size-cells = <0x01>;
	};

	cpwcn_gnss {
		compatible = "sprd,integrate_gnss";
		sprd,name = "wcn_gnss";
		sprd,syscon-ap-apb = <0x2e>;
		sprd,syscon-ap-pmu = <0x3c>;
		sprd,syscon-ap-pub-apb = <0xb2>;
		sprd,syscon-anlg-wrap-wcn = <0xb3>;
		sprd,syscon-anlg-phy-g6 = <0x3b>;
		sprd,ctrl-probe-num = <0x02>;
		sprd,ctrl-reg = <0x1578 0x30a0 0x2100 0x20cc 0x20b0 0x157c>;
		sprd,ctrl-mask = <0x3300000 0xffff 0x3000000 0x80000 0xa00 0x40>;
		sprd,ctrl-value = <0x300000 0x808 0x3000000 0x80000 0xa00 0x40>;
		sprd,ctrl-rw-offset = <0x1000 0x00 0x2000 0x2000 0x2000 0x1000>;
		sprd,ctrl-us-delay = <0x0a 0x0a 0x0a 0x0a 0x0a 0x0a>;
		sprd,ctrl-type = <0x00 0x02 0x01 0x01 0x01 0x00>;
		sprd,ctrl-shutdown-reg = <0x257c 0x10b0>;
		sprd,ctrl-shutdown-mask = <0x40 0x800>;
		sprd,ctrl-shutdown-value = <0x40 0x800>;
		sprd,ctrl-shutdown-rw-offset = <0x2000 0x1000>;
		sprd,ctrl-shutdown-us-delay = <0x0a 0x0a>;
		sprd,ctrl-shutdown-type = <0x00 0x01>;
		reg = <0x00 0x88300000 0x00 0x100000>;
		sprd,file-length = <0x100000>;
		memory_region = <0xb7>;
		vddwcn-supply = <0xb5>;
		#address-cells = <0x01>;
		#size-cells = <0x01>;
	};

	sipc@88180000 {
		compatible = "sprd,sipc-v1";
		sprd,name = "sipc-wcn";
		sprd,dst = <0x03 0x05>;
		sprd,smem-info = <0x88180000 0x180000 0x180000>;
	};

	spipe_cpwcn {
		compatible = "sprd,spipe";
		sprd,name = "spipe_wcn";
		sprd,dst = <0x03>;
		sprd,channel = <0x04>;
		sprd,ringnr = <0x10>;
		sprd,size-rxbuf = <0x2400>;
		sprd,size-txbuf = <0x2400>;
	};

	wcn_wifi_cmd {
		compatible = "sprd,swcnblk";
		sprd,name = "wcn_wifi_cmd";
		sprd,dst = <0x03>;
		sprd,channel = <0x07>;
		sprd,tx-blksize = <0x800>;
		sprd,tx-blknum = <0x04>;
		sprd,rx-blksize = <0x800>;
		sprd,rx-blknum = <0x10>;
	};

	wcn_wifi_data0 {
		compatible = "sprd,swcnblk";
		sprd,name = "wcn_wifi_data0";
		sprd,dst = <0x03>;
		sprd,channel = <0x08>;
		sprd,tx-blksize = <0x680>;
		sprd,tx-blknum = <0x40>;
		sprd,rx-blksize = <0x680>;
		sprd,rx-blknum = <0x100>;
	};

	wcn_wifi_data1 {
		compatible = "sprd,swcnblk";
		sprd,name = "wcn_wifi_data1";
		sprd,dst = <0x03>;
		sprd,channel = <0x09>;
		sprd,tx-blksize = <0x680>;
		sprd,tx-blknum = <0x40>;
		sprd,rx-blksize = <0x00>;
		sprd,rx-blknum = <0x00>;
	};

	wcn_bt {
		compatible = "sprd,wcn_internal_chip";
		sprd,name = "ttyBT";
		sprd,dst = <0x03>;
		sprd,channel = <0x04>;
		sprd,tx_bufid = <0x0b>;
		sprd,rx_bufid = <0x0a>;
	};

	wcn_fm {
		compatible = "sprd,wcn_internal_chip";
		sprd,name = "fm";
		sprd,dst = <0x03>;
		sprd,tx_channel = <0x04>;
		sprd,rx_channel = <0x04>;
		sprd,tx_bufid = <0x0e>;
		sprd,rx_bufid = <0x0d>;
	};

	gnss_common_ctl {
		compatible = "sprd,gnss_common_ctl";
		sprd,name = "gnss_common_ctl";
	};

	sipc@8841b000 {
		compatible = "sprd,sipc-v1";
		sprd,name = "sipc-gnss";
		sprd,dst = <0x04 0x06>;
		sprd,smem-info = <0x8841b000 0x11b000 0x32000>;
	};

	spipe_gnss {
		compatible = "sprd,spipe";
		sprd,name = "sttygnss0";
		sprd,dst = <0x04>;
		sprd,channel = <0x04>;
		sprd,ringnr = <0x01>;
		sprd,size-rxbuf = <0x19000>;
		sprd,size-txbuf = <0xc800>;
	};

	battery {
		compatible = "sprd,sprd-battery";
		status = "okay";
		battery-adapt-support = <0x00>;
		battery-adapt-fun = <0x00>;
		chg-end-vol = <0x10fe>;
		chg-end-vol-check = <0x10ea>;
		chg-bat-safety-vol = <0x114e>;
		fchg-vol = <0x2328>;
		rechg-vol = <0x10ae>;
		adp-cdp-cur = <0x47e>;
		adp-dcp-cur = <0x47e>;
		adp-sdp-cur = <0x226>;
		adp-unknown-cur = <0x226>;
		adp-fchg-cur = <0xbb8>;
		adp-cdp-cur-limit = <0x5dc>;
		adp-dcp-cur-limit = <0xbb8>;
		adp-sdp-cur-limit = <0x1f4>;
		adp-fchg-cur-limit = <0x7d0>;
		adp-unknown-cur-limit = <0x1f4>;
		ovp-stop = <0x1964>;
		ovp-restart = <0x16a8>;
		fchg-ovp-stop = <0x2af8>;
		fchg-ovp-restart = <0x2710>;
		chg-timeout = <0x5460>;
		chg-rechg-timeout = <0x1518>;
		chg-end-cur = <0x78>;
		chg-polling-time = <0x0a>;
		chg-polling-time-fast = <0x01>;
		cap-one-per-time = <0x1e>;
		chg-full-condition = <0x00>;
		temp-support = <0x00>;
		temp-comp-res = <0x06>;
		temp-tab-val = <0x41c 0x3b9 0x35a 0x2fa 0x29f 0x248 0x1f8 0x1b2 0x174 0x13e 0x10f 0xea 0xc6 0xa5 0x8c 0x77 0x68 0x58>;
		temp-tab-temp = <0x2ee 0x320 0x352 0x384 0x3b6 0x3e8 0x41a 0x44c 0x47e 0x4b0 0x4e2 0x514 0x546 0x578 0x5aa 0x5dc 0x60e 0x640>;
		jeita-temp-tab = <0x384 0x3e8 0x44c 0x5aa 0x5dc>;
		jeita-temp-recovery-tab = <0x3a2 0x406 0x46a 0x58c 0x5be>;
		jeita-cur-tab = <0x00 0x64 0x1f4 0x7fff 0x2bc 0x00>;
		jeita-cccv-tab = <0x1068 0x1068 0x10fe 0x10fe 0x10fe 0x10fe>;
		fgu-mode = <0x00>;
		alm-soc = <0x05>;
		alm-vol = <0xd7a>;
		soft-vbat-uvlo = <0xbea>;
		rint = <0x140>;
		cnom = <0xadc>;
		rsense-real = <0xc8>;
		rsense-spec = <0xc8>;
		relax-current = <0x32>;
		fgu-cal-ajust = <0x00>;
		ocv-tab-vol = <0x1108 0x1099 0x105d 0x1025 0xff1 0xfc2 0xf97 0xf71 0xf46 0xf1a 0xefc 0xee5 0xed3 0xec6 0xebe 0xeb5 0xea6 0xe8e 0xe67 0xe4a 0xd48>;
		ocv-tab-cap = <0x64 0x5f 0x5a 0x55 0x50 0x4b 0x46 0x41 0x3c 0x37 0x32 0x2d 0x28 0x23 0x1e 0x19 0x14 0x0f 0x0a 0x05 0x00>;
		cnom-temp-tab = <0x3fc 0x708 0x3f2 0x514 0x3e8 0x42e 0x3de 0x3e8>;
		rint-temp-tab = <0x3fc 0xc8 0x3f2 0x1c2 0x3e8 0x28a 0x3de 0x44c>;
		charger-det-gpios = <0x19 0x00 0x00>;
		io-channels = <0xb8 0x01 0xb8 0x0a 0xb8 0x24 0xb8 0x10>;
		io-channel-names = "adc_temp\0adc_vbat\0adc_vchg\0adc_isense";
	};

	sprd-headset {
		compatible = "sprd,sc2721-headset\0sprd,sc2731-headset";
		status = "okay";
		jack-type = <0x00>;
		io-channels = <0xb8 0x37 0xb8 0x30 0xb8 0x31 0xb8 0x32 0xb8 0x33>;
		io-channel-names = "headset\0headmic_in_big\0headmic_in_little\0l_int_big\0l_int_little";
		gpios = <0x19 0x03 0x00 0x19 0x08 0x00 0x19 0x0c 0x00 0x19 0x05 0x00 0x19 0x0d 0x00>;
		gpio-trigger-levels = <0x01 0x01 0x01 0x01 0x01>;
		gpio-dbnc-intervals = <0x0a 0x64 0x64 0x64 0x64>;
		gpio-names = "button\0detect_l\0detect_h\0detect_mic\0detect_all";
		adc-threshold-3pole-detect = <0xbee>;
		sprd,adc-gnd = <0x150>;
		sprd,stable-value = <0x8af>;
		sprd,coefficient = <0xe573c>;
		irq-threshold-button = <0x09>;
		linux,phandle = <0xb9>;
		phandle = <0xb9>;

		headset-button@0 {
			adc-min = <0x00>;
			adc-max = <0x1ea>;
			code = <0xe2>;
		};

		headset-button@1 {
			adc-min = <0x21c>;
			adc-max = <0x3fc>;
			code = <0x73>;
		};

		headset-button@2 {
			adc-min = <0x442>;
			adc-max = <0x960>;
			code = <0x72>;
		};
	};

	sound@0 {
		compatible = "sprd,vbc-r1p0v3-codec-sc2721\0sprd,vbc-r1p0v3-codec-sc2731";
		status = "okay";
		sprd-audio-card,name = "sprdphone";
		sprd-audio-card,widgets = "Headphone\0inter HP PA\0Speaker\0inter Spk PA\0Speaker\0inter Ear PA";
		sprd-audio-card,routing = "HPMIC\0HP Mic Jack\0MIC\0Mic Jack\0AUXMIC\0Aux Mic Jack\0inter HP PA\0HP PA\0inter Spk PA\0Spk PA\0inter Ear PA\0EAR\0DMIC\0DMic Jack\0DMIC1\0DMic1 Jack\0Aud input\0AD Clk\0Aud input1\0AD Clk\0Aud input\0Digital ADCL Switch\0Aud input\0Digital ADCR Switch\0Aud input1\0Digital ADC1L Switch\0Aud input1\0Digital ADC1R Switch";
		sprd-audio-card,headset = <0xb9>;
		sprd-audio-card,fm-open-src = <0x01>;
		sprd-audio-card,fm-hw-rate = <0x7d00>;
		sprd-audio-card,codec-replace-adc-rate = <0xbb80>;
		sprd,smartamp-boost-names = "boost_enable\0boost_mode";
		sprd,smartamp-boost-gpios = <0x10 0x79 0x00 0x10 0x55 0x00>;

		sprd-audio-card,dai-link@0 {

			plat {
				sound-dai = <0xba>;
			};

			cpu {
				sound-dai = <0xbb 0x00>;
			};

			codec {
				sound-dai = <0xbc 0x00>;
			};
		};

		sprd-audio-card,dai-link@1 {

			plat {
				sound-dai = <0xba>;
			};

			cpu {
				sound-dai = <0xbd 0x00>;
			};

			codec {
				sound-dai = <0xbc 0x01>;
			};
		};

		sprd-audio-card,dai-link@2 {

			plat {
				sound-dai = <0xba>;
			};

			cpu {
				sound-dai = <0xbb 0x01>;
			};

			codec {
				sound-dai = <0xbc 0x03>;
			};
		};

		sprd-audio-card,dai-link@3 {

			plat {
				sound-dai = <0xba>;
			};

			cpu {
				sound-dai = <0xbd 0x01>;
			};

			codec {
				sound-dai = <0xbc 0x04>;
			};
		};

		sprd-audio-card,dai-link@4 {
			ops = <0x00>;

			plat {
				sound-dai = <0xba>;
			};

			cpu {
				sound-dai = <0xbb 0x02>;
			};

			codec {
				sound-dai = <0xbc 0x05>;
			};
		};

		sprd-audio-card,dai-link@5 {

			plat {
				sound-dai = <0xba>;
			};

			cpu {
				sound-dai = <0xbb 0x03>;
			};

			codec {
				sound-dai = <0xbc 0x06>;
			};
		};
	};

	sound@1 {
		compatible = "sprd,i2s-null-codec";
		status = "okay";
		sprd-audio-card,name = "all-i2s";

		sprd-audio-card,dai-link@0 {

			plat {
				sound-dai = <0xbe>;
			};

			cpu {
				sound-dai = <0xbf>;
			};

			codec {
				sound-dai = <0x00 0x00>;
			};
		};
	};

	lcds {

		lcd8802@8802 {
			work-mode = <0x01>;
			bpp = <0x18>;
			lane-number = <0x02>;
			need-check-esd = <0x00>;
			esd-timeout = <0x3e8>;
			esd-check-reg = <0x0b>;
			esd-return-code = <0x00>;
			fps = <0x3c>;
			width-mm = <0x3d>;
			height-mm = <0x79>;
			panel-name = "lcd_st7701s_mipi";
			power-on-sequence = <0x32 0x01 0x05 0x32 0x00 0x05 0x32 0x01 0x14>;
			power-off-sequence = <0x32 0x01 0x14>;
			init-data = [29 00 00 06 ff 77 01 00 00 13 23 00 00 02 ef 08 29 00 00 06 ff 77 01 00 00 10 29 00 00 03 c0 f7 02 29 00 00 03 c1 12 0c 29 00 00 03 c2 27 02 23 00 00 02 c6 21 23 00 00 02 cc 30 29 00 00 11 b0 00 04 15 13 19 0c 11 0a 08 24 05 13 11 15 19 18 29 00 00 11 b1 00 04 11 12 17 0a 0f 09 08 26 09 16 14 19 1e 18 29 00 00 06 ff 77 01 00 00 11 23 00 00 02 b0 4d 23 00 00 02 b1 68 23 00 00 02 b2 89 23 00 00 02 b3 80 23 00 00 02 b5 49 23 00 00 02 b7 85 23 00 00 02 b8 10 23 00 00 02 b9 10 23 00 00 02 c1 78 23 00 00 02 c2 78 23 00 00 02 d0 88 29 00 00 04 e0 00 00 02 29 00 00 0c e1 0a 96 0c 96 0b 96 0d 96 00 44 44 29 00 00 0e e2 33 33 33 33 cf 00 d1 00 d0 00 d2 00 00 29 00 00 05 e3 00 00 33 33 29 00 00 03 e4 44 44 29 00 00 11 e5 0c d0 28 96 0e d2 28 96 10 d4 28 96 12 d6 28 96 29 00 00 05 e6 00 00 33 33 29 00 00 03 e7 44 44 29 00 00 11 e8 0d d1 28 96 0f d3 28 96 11 d5 28 96 13 d7 28 96 29 00 00 08 eb 02 02 4e 4e ee 44 00 29 00 00 03 ec 00 00 29 00 00 11 ed ff f1 04 56 72 3f ff ff ff ff f3 27 65 40 1f ff 29 00 00 07 ef 08 08 08 45 3f 54 29 00 00 06 ff 77 01 00 00 13 29 00 00 03 e8 00 0e 29 00 00 06 ff 77 01 00 00 00 29 00 00 06 ff 77 01 00 00 13 29 00 00 03 e8 00 0c 29 00 00 03 e8 00 00 29 00 00 06 ff 77 01 00 00 00 23 00 00 02 35 00 13 78 00 01 11 13 14 00 01 29];
			sleep-in = [13 0a 00 01 28 13 78 00 01 10];
			sleep-out = [13 78 00 01 11 13 64 00 01 29];
			linux,phandle = <0xc0>;
			phandle = <0xc0>;

			display-timings {
				clock-frequency = <0x75d8c>;
				hactive = <0x1e0>;
				vactive = <0x3c0>;
				hfront-porch = <0x28>;
				hback-porch = <0x24>;
				hsync-len = <0x12>;
				vfront-porch = <0x12>;
				vback-porch = <0x12>;
				vsync-len = <0x08>;
			};
		};

		lcd9504@9504 {
			work-mode = <0x01>;
			bpp = <0x18>;
			lane-number = <0x02>;
			need-check-esd = <0x00>;
			esd-timeout = <0x3e8>;
			esd-check-reg = <0x0b>;
			esd-return-code = <0x00>;
			fps = <0x3c>;
			width-mm = <0x3d>;
			height-mm = <0x79>;
			panel-name = "lcd_gc9504_mipi";
			power-on-sequence = <0x32 0x01 0x05 0x32 0x00 0x0a 0x32 0x01 0x78>;
			power-off-sequence = <0x32 0x01 0x14>;
			init-data = [29 00 00 06 f0 55 aa 52 08 00 29 00 00 03 f6 5a 87 23 00 00 02 c1 3f 23 00 00 02 c2 0e 23 00 00 02 c6 f8 23 00 00 02 c9 10 23 00 00 02 cd 25 23 00 00 02 f8 8a 23 00 00 02 ac 45 23 00 00 02 a7 47 23 00 00 02 a0 88 29 00 00 05 fa 08 08 00 04 23 00 00 02 a3 2e 29 00 00 04 fd 28 3c 00 23 00 00 02 9a 85 23 00 00 02 9b 5d 29 00 00 03 82 3b 3b 23 00 00 02 b1 10 29 00 00 03 7a 13 1a 29 00 00 03 7b 13 1a 29 00 00 05 86 99 a3 a3 51 29 00 00 21 6d 00 1d 0a 10 08 1f 1e 1e 1e 1e 1e 1e 1e 1e 1e 1e 1e 1e 1e 1e 1e 1e 1e 1e 1e 1e 1f 01 0f 09 1d 00 29 00 00 11 64 18 04 03 c7 03 03 18 03 03 c6 03 03 0b 7a 0b 7a 29 00 00 11 67 18 02 03 c5 03 03 18 01 03 c4 03 03 0b 7a 0b 7a 29 00 00 09 60 18 06 0b 7a 18 02 0b 7a 29 00 00 09 63 18 02 0b 7a 18 05 0b 7a 29 00 00 08 69 14 22 14 22 44 22 08 29 00 00 35 d1 00 00 00 09 00 20 00 35 00 48 00 6c 00 8a 00 bd 00 e7 01 29 01 63 01 ba 02 02 02 04 02 48 02 98 02 d2 03 23 03 5a 03 a0 03 b4 03 c9 03 d7 03 fa 03 fc 03 ff 29 00 00 35 d2 00 00 00 09 00 20 00 35 00 48 00 6c 00 8a 00 bd 00 e7 01 29 01 63 01 ba 02 02 02 04 02 48 02 98 02 d2 03 23 03 5a 03 a0 03 b4 03 c9 03 d7 03 fa 03 fc 03 ff 29 00 00 35 d3 00 00 00 09 00 20 00 35 00 48 00 6c 00 8a 00 bd 00 e7 01 29 01 63 01 ba 02 02 02 04 02 48 02 98 02 d2 03 23 03 5a 03 a0 03 b4 03 c9 03 d7 03 fa 03 fc 03 ff 29 00 00 35 d4 00 00 00 09 00 20 00 35 00 48 00 6c 00 8a 00 bd 00 e7 01 29 01 63 01 ba 02 02 02 04 02 48 02 98 02 d2 03 23 03 5a 03 a0 03 b4 03 c9 03 d7 03 fa 03 fc 03 ff 29 00 00 35 d5 00 00 00 09 00 20 00 35 00 48 00 6c 00 8a 00 bd 00 e7 01 29 01 63 01 ba 02 02 02 04 02 48 02 98 02 d2 03 23 03 5a 03 a0 03 b4 03 c9 03 d7 03 fa 03 fc 03 ff 29 00 00 35 d6 00 00 00 09 00 20 00 35 00 48 00 6c 00 8a 00 bd 00 e7 01 29 01 63 01 ba 02 02 02 04 02 48 02 98 02 d2 03 23 03 5a 03 a0 03 b4 03 c9 03 d7 03 fa 03 fc 03 ff 13 78 00 01 11 13 14 00 01 29];
			sleep-in = [23 14 00 02 6c 60 23 00 00 02 b1 00 29 14 00 05 fa 7f 00 00 00 23 0a 00 02 6c 50 23 32 00 02 28 00 23 14 00 02 10 00 29 00 00 06 f0 55 aa 52 08 00 23 00 00 02 c2 ce 23 00 00 02 c3 cd 23 00 00 02 c6 fc 23 00 00 02 c5 03 23 00 00 02 cd 64 23 00 00 02 c4 ff 23 00 00 02 c9 cd 29 00 00 03 f6 5a 87 29 00 00 04 fd aa aa 0a 29 00 00 03 fe 6a 0a 29 00 00 03 78 2a aa 29 00 00 03 92 17 08 29 00 00 03 77 aa 2a 29 00 00 03 76 aa aa 23 00 00 02 84 00 29 00 00 03 78 2b ba 23 00 00 02 89 73 23 00 00 02 88 3a 23 00 00 02 85 b0 29 00 00 03 76 eb aa 23 00 00 02 94 80 29 00 00 04 87 04 07 30 23 00 00 02 93 27 23 00 00 02 af 02];
			sleep-out = [29 00 00 06 f0 55 aa 52 08 00 29 00 00 03 f6 5a 87 23 00 00 02 c1 3f 23 00 00 02 c2 0e 23 00 00 02 c6 f8 23 00 00 02 c9 10 23 00 00 02 cd 25 23 00 00 02 f8 8a 23 00 00 02 ac 45 23 00 00 02 a7 47 23 00 00 02 a0 88 29 00 00 05 fa 08 08 00 04 23 00 00 02 a3 2e 29 00 00 04 fd 28 3c 00 23 00 00 02 9a 85 23 00 00 02 9b 5d 29 00 00 03 82 3b 3b 23 00 00 02 b1 10 29 00 00 03 7a 13 1a 29 00 00 03 7b 13 1a 29 00 00 05 86 99 a3 a3 51 29 00 00 21 6d 00 1d 0a 10 08 1f 1e 1e 1e 1e 1e 1e 1e 1e 1e 1e 1e 1e 1e 1e 1e 1e 1e 1e 1e 1e 1f 01 0f 09 1d 00 29 00 00 11 64 18 04 03 c7 03 03 18 03 03 c6 03 03 0b 7a 0b 7a 29 00 00 11 67 18 02 03 c5 03 03 18 01 03 c4 03 03 0b 7a 0b 7a 29 00 00 09 60 18 06 0b 7a 18 02 0b 7a 29 00 00 09 63 18 02 0b 7a 18 05 0b 7a 29 00 00 08 69 14 22 14 22 44 22 08 23 00 00 02 11 00 23 00 00 02 29 00];
			linux,phandle = <0xc3>;
			phandle = <0xc3>;

			display-timings {
				clock-frequency = <0x704e0>;
				hactive = <0x1e0>;
				vactive = <0x3c0>;
				hfront-porch = <0x18>;
				hback-porch = <0x18>;
				hsync-len = <0x08>;
				vfront-porch = <0x14>;
				vback-porch = <0x14>;
				vsync-len = <0x02>;
			};
		};

		lcd950403@950403 {
			work-mode = <0x01>;
			bpp = <0x18>;
			lane-number = <0x02>;
			need-check-esd = <0x00>;
			esd-timeout = <0x3e8>;
			esd-check-reg = <0x0b>;
			esd-return-code = <0x00>;
			fps = <0x3c>;
			width-mm = <0x3d>;
			height-mm = <0x79>;
			panel-name = "lcd_gc9504_id3_mipi";
			power-on-sequence = <0x32 0x01 0x05 0x32 0x00 0x0a 0x32 0x01 0x78>;
			power-off-sequence = <0x32 0x01 0x14>;
			init-data = [29 00 00 06 f0 55 aa 52 08 00 29 00 00 03 f6 5a 87 23 00 00 02 c9 10 23 00 00 02 cd 25 23 00 00 02 f8 8a 23 00 00 02 ac 45 23 00 00 02 a7 47 23 00 00 02 a0 bb 29 00 00 05 86 99 a3 a3 31 29 00 00 05 fa 8f 00 00 04 23 00 00 02 a3 6e 29 00 00 04 fd 3c 3c 00 23 00 00 02 9a 9a 23 00 00 02 9b 72 29 00 00 03 82 50 50 23 00 00 02 b1 10 29 00 00 03 7a 0f 13 29 00 00 03 7b 0f 13 29 00 00 21 6d 07 1e 01 00 1f 09 0f 0b 0d 1e 1e 1e 1e 1e 1e 1e 1e 1e 1e 1e 1e 1e 1e 0e 0c 10 0a 1f 00 02 1e 08 29 00 00 09 60 38 0a 6d 6d 38 09 6d 6d 29 00 00 09 63 33 be 6d 6d 33 bf 6d 6d 29 00 00 11 64 28 06 03 c2 03 03 28 05 03 c3 03 03 6d 6d 6d 6d 29 00 00 11 67 28 04 03 c4 03 03 28 03 03 c5 03 03 6d 6d 6d 6d 29 00 00 11 65 28 02 03 c6 03 03 28 01 03 c7 03 03 6d 6d 6d 6d 29 00 00 11 66 20 00 03 c0 03 03 20 01 03 c1 03 03 6d 6d 6d 6d 29 00 00 08 69 14 22 14 22 44 22 08 23 00 00 02 6b 07 29 00 00 35 d1 00 00 00 00 00 05 00 14 00 32 00 6f 00 80 00 a5 00 df 01 35 01 71 01 c4 02 00 02 04 02 38 02 6e 02 8a 02 b0 02 c3 02 e2 02 f3 03 0d 03 23 03 3f 03 54 03 ff 29 00 00 35 d2 00 00 00 00 00 05 00 14 00 32 00 6f 00 80 00 a5 00 df 01 35 01 71 01 c4 02 00 02 04 02 38 02 6e 02 8a 02 b0 02 c3 02 e2 02 f3 03 0d 03 23 03 3f 03 54 03 ff 29 00 00 35 d3 00 00 00 00 00 05 00 14 00 32 00 6f 00 80 00 a5 00 df 01 35 01 71 01 c4 02 00 02 04 02 38 02 6e 02 8a 02 b0 02 c3 02 e2 02 f3 03 0d 03 23 03 3f 03 54 03 ff 29 00 00 35 d4 00 00 00 00 00 05 00 14 00 32 00 6f 00 80 00 a5 00 df 01 35 01 71 01 c4 02 00 02 04 02 38 02 6e 02 8a 02 b0 02 c3 02 e2 02 f3 03 0d 03 23 03 3f 03 54 03 ff 29 00 00 35 d5 00 00 00 00 00 05 00 14 00 32 00 6f 00 80 00 a5 00 df 01 35 01 71 01 c4 02 00 02 04 02 38 02 6e 02 8a 02 b0 02 c3 02 e2 02 f3 03 0d 03 23 03 3f 03 54 03 ff 29 00 00 35 d6 00 00 00 00 00 05 00 14 00 32 00 6f 00 80 00 a5 00 df 01 35 01 71 01 c4 02 00 02 04 02 38 02 6e 02 8a 02 b0 02 c3 02 e2 02 f3 03 0d 03 23 03 3f 03 54 03 ff 13 78 00 01 11 13 14 00 01 29];
			sleep-in = [23 14 00 02 6c 60 23 00 00 02 b1 00 29 14 00 05 fa 7f 00 00 00 23 0a 00 02 6c 50 23 32 00 02 28 00 23 14 00 02 10 00 29 00 00 06 f0 55 aa 52 08 00 23 00 00 02 c2 ce 23 00 00 02 c3 cd 23 00 00 02 c6 fc 23 00 00 02 c5 03 23 00 00 02 cd 64 23 00 00 02 c4 ff 23 00 00 02 c9 cd 29 00 00 03 f6 5a 87 29 00 00 04 fd aa aa 0a 29 00 00 03 fe 6a 0a 29 00 00 03 78 2a aa 29 00 00 03 92 17 08 29 00 00 03 77 aa 2a 29 00 00 03 76 aa aa 23 00 00 02 84 00 29 00 00 03 78 2b ba 23 00 00 02 89 73 23 00 00 02 88 3a 23 00 00 02 85 b0 29 00 00 03 76 eb aa 23 00 00 02 94 80 29 00 00 04 87 04 07 30 23 00 00 02 93 27 23 00 00 02 af 02];
			sleep-out = [29 00 00 06 f0 55 aa 52 08 00 29 00 00 03 f6 5a 87 23 00 00 02 c1 3f 23 00 00 02 c2 0e 23 00 00 02 c6 f8 23 00 00 02 c9 10 23 00 00 02 cd 25 23 00 00 02 f8 8a 23 00 00 02 ac 45 23 00 00 02 a7 47 23 00 00 02 a0 88 29 00 00 05 fa 08 08 00 04 23 00 00 02 a3 2e 29 00 00 04 fd 28 3c 00 23 00 00 02 9a 85 23 00 00 02 9b 5d 29 00 00 03 82 3b 3b 23 00 00 02 b1 10 29 00 00 03 7a 13 1a 29 00 00 03 7b 13 1a 29 00 00 05 86 99 a3 a3 51 29 00 00 21 6d 00 1d 0a 10 08 1f 1e 1e 1e 1e 1e 1e 1e 1e 1e 1e 1e 1e 1e 1e 1e 1e 1e 1e 1e 1e 1f 01 0f 09 1d 00 29 00 00 11 64 18 04 03 c7 03 03 18 03 03 c6 03 03 0b 7a 0b 7a 29 00 00 11 67 18 02 03 c5 03 03 18 01 03 c4 03 03 0b 7a 0b 7a 29 00 00 09 60 18 06 0b 7a 18 02 0b 7a 29 00 00 09 63 18 02 0b 7a 18 05 0b 7a 29 00 00 08 69 14 22 14 22 44 22 08 23 00 00 02 11 00 23 00 00 02 29 00];
			linux,phandle = <0xc2>;
			phandle = <0xc2>;

			display-timings {
				clock-frequency = <0x704e0>;
				hactive = <0x1e0>;
				vactive = <0x3c0>;
				hfront-porch = <0x14>;
				hback-porch = <0x14>;
				hsync-len = <0x0a>;
				vfront-porch = <0x0c>;
				vback-porch = <0x1e>;
				vsync-len = <0x08>;
			};
		};

		lcd950404@950404 {
			work-mode = <0x01>;
			bpp = <0x18>;
			lane-number = <0x02>;
			need-check-esd = <0x00>;
			esd-timeout = <0x3e8>;
			esd-check-reg = <0x0b>;
			esd-return-code = <0x00>;
			fps = <0x3c>;
			width-mm = <0x3d>;
			height-mm = <0x79>;
			panel-name = "lcd_gc9504_id4_mipi";
			power-on-sequence = <0x32 0x01 0x05 0x32 0x00 0x0a 0x32 0x01 0x78>;
			power-off-sequence = <0x32 0x01 0x14>;
			init-data = [29 00 00 06 f0 55 aa 52 08 00 29 00 00 03 f6 5a 87 23 00 00 02 c1 3f 23 00 00 02 c2 0e 23 00 00 02 c6 f8 23 00 00 02 c9 10 23 00 00 02 cd 25 23 00 00 02 f8 8a 23 00 00 02 ac 45 23 00 00 02 a7 47 23 00 00 02 a0 88 29 00 00 05 fa 08 08 00 04 23 00 00 02 a3 2e 29 00 00 04 fd 28 3c 00 23 00 00 02 9a 85 23 00 00 02 9b 5d 29 00 00 03 82 3b 3b 23 00 00 02 b1 10 29 00 00 03 7a 13 1a 29 00 00 03 7b 13 1a 29 00 00 05 86 99 a3 a3 51 29 00 00 21 6d 00 1d 0a 10 08 1f 1e 1e 1e 1e 1e 1e 1e 1e 1e 1e 1e 1e 1e 1e 1e 1e 1e 1e 1e 1e 1f 01 0f 09 1d 00 29 00 00 11 64 18 04 03 c7 03 03 18 03 03 c6 03 03 0b 7a 0b 7a 29 00 00 11 67 18 02 03 c5 03 03 18 01 03 c4 03 03 0b 7a 0b 7a 29 00 00 09 60 18 06 0b 7a 18 02 0b 7a 29 00 00 09 63 18 02 0b 7a 18 05 0b 7a 29 00 00 08 69 14 22 14 22 44 22 08 29 00 00 35 d1 00 00 00 09 00 20 00 35 00 48 00 6c 00 8a 00 bd 00 e7 01 29 01 63 01 ba 02 02 02 04 02 48 02 98 02 d2 03 23 03 5a 03 a0 03 b4 03 c9 03 d7 03 fa 03 fc 03 ff 29 00 00 35 d2 00 00 00 09 00 20 00 35 00 48 00 6c 00 8a 00 bd 00 e7 01 29 01 63 01 ba 02 02 02 04 02 48 02 98 02 d2 03 23 03 5a 03 a0 03 b4 03 c9 03 d7 03 fa 03 fc 03 ff 29 00 00 35 d3 00 00 00 09 00 20 00 35 00 48 00 6c 00 8a 00 bd 00 e7 01 29 01 63 01 ba 02 02 02 04 02 48 02 98 02 d2 03 23 03 5a 03 a0 03 b4 03 c9 03 d7 03 fa 03 fc 03 ff 29 00 00 35 d4 00 00 00 09 00 20 00 35 00 48 00 6c 00 8a 00 bd 00 e7 01 29 01 63 01 ba 02 02 02 04 02 48 02 98 02 d2 03 23 03 5a 03 a0 03 b4 03 c9 03 d7 03 fa 03 fc 03 ff 29 00 00 35 d5 00 00 00 09 00 20 00 35 00 48 00 6c 00 8a 00 bd 00 e7 01 29 01 63 01 ba 02 02 02 04 02 48 02 98 02 d2 03 23 03 5a 03 a0 03 b4 03 c9 03 d7 03 fa 03 fc 03 ff 29 00 00 35 d6 00 00 00 09 00 20 00 35 00 48 00 6c 00 8a 00 bd 00 e7 01 29 01 63 01 ba 02 02 02 04 02 48 02 98 02 d2 03 23 03 5a 03 a0 03 b4 03 c9 03 d7 03 fa 03 fc 03 ff 13 78 00 01 11 13 14 00 01 29];
			sleep-in = [23 14 00 02 6c 60 23 00 00 02 b1 00 29 14 00 05 fa 7f 00 00 00 23 0a 00 02 6c 50 23 32 00 02 28 00 23 14 00 02 10 00 29 00 00 06 f0 55 aa 52 08 00 23 00 00 02 c2 ce 23 00 00 02 c3 cd 23 00 00 02 c6 fc 23 00 00 02 c5 03 23 00 00 02 cd 64 23 00 00 02 c4 ff 23 00 00 02 c9 cd 29 00 00 03 f6 5a 87 29 00 00 04 fd aa aa 0a 29 00 00 03 fe 6a 0a 29 00 00 03 78 2a aa 29 00 00 03 92 17 08 29 00 00 03 77 aa 2a 29 00 00 03 76 aa aa 23 00 00 02 84 00 29 00 00 03 78 2b ba 23 00 00 02 89 73 23 00 00 02 88 3a 23 00 00 02 85 b0 29 00 00 03 76 eb aa 23 00 00 02 94 80 29 00 00 04 87 04 07 30 23 00 00 02 93 27 23 00 00 02 af 02];
			sleep-out = [29 00 00 06 f0 55 aa 52 08 00 29 00 00 03 f6 5a 87 23 00 00 02 c1 3f 23 00 00 02 c2 0e 23 00 00 02 c6 f8 23 00 00 02 c9 10 23 00 00 02 cd 25 23 00 00 02 f8 8a 23 00 00 02 ac 45 23 00 00 02 a7 47 23 00 00 02 a0 88 29 00 00 05 fa 08 08 00 04 23 00 00 02 a3 2e 29 00 00 04 fd 28 3c 00 23 00 00 02 9a 85 23 00 00 02 9b 5d 29 00 00 03 82 3b 3b 23 00 00 02 b1 10 29 00 00 03 7a 13 1a 29 00 00 03 7b 13 1a 29 00 00 05 86 99 a3 a3 51 29 00 00 21 6d 00 1d 0a 10 08 1f 1e 1e 1e 1e 1e 1e 1e 1e 1e 1e 1e 1e 1e 1e 1e 1e 1e 1e 1e 1e 1f 01 0f 09 1d 00 29 00 00 11 64 18 04 03 c7 03 03 18 03 03 c6 03 03 0b 7a 0b 7a 29 00 00 11 67 18 02 03 c5 03 03 18 01 03 c4 03 03 0b 7a 0b 7a 29 00 00 09 60 18 06 0b 7a 18 02 0b 7a 29 00 00 09 63 18 02 0b 7a 18 05 0b 7a 29 00 00 08 69 14 22 14 22 44 22 08 23 00 00 02 11 00 23 00 00 02 29 00];
			linux,phandle = <0xc1>;
			phandle = <0xc1>;

			display-timings {
				clock-frequency = <0x704e0>;
				hactive = <0x1e0>;
				vactive = <0x3c0>;
				hfront-porch = <0x18>;
				hback-porch = <0x18>;
				hsync-len = <0x08>;
				vfront-porch = <0x14>;
				vback-porch = <0x14>;
				vsync-len = <0x02>;
			};
		};
	};

	sprd-panel-if {
		compatible = "sprd-panel-if";
		#address-cells = <0x01>;
		#size-cells = <0x00>;
		panel-drivers = <0xc0 0xc1 0xc2 0xc3 0xc4>;

		port@1 {
			reg = <0x01>;

			endpoint@0 {
				remote-endpoint = <0xc5>;
				linux,phandle = <0x38>;
				phandle = <0x38>;
			};
		};
	};

	firmware {

		android {
			compatible = "android,firmware";

			vbmeta {
				compatible = "android,vbmeta";
				parts = "vbmeta,boot,recovery,system,vendor";
			};

		};
	};

	thermal-zones {

		cpu-thmzone {
			polling-delay-passive = <0x64>;
			polling-delay = <0x3e8>;
			sustainable-power = <0x7d0>;
			thermal-sensors = <0xc6 0x01>;

			trips {

				trip-point@0 {
					temperature = <0x11170>;
					hysteresis = <0x3e8>;
					type = "passive";
				};

				trip-point@1 {
					temperature = <0x14c08>;
					hysteresis = <0x3e8>;
					type = "passive";
					linux,phandle = <0xc7>;
					phandle = <0xc7>;
				};

				cpu_crit {
					temperature = <0x1adb0>;
					hysteresis = <0x7d0>;
					type = "critical";
				};
			};

			cooling-maps {

				map0 {
					trip = <0xc7>;
					contribution = <0x400>;
					cooling-device = <0xc8 0xffffffff 0xffffffff>;
				};
			};
		};

		gpu-thmzone {
			polling-delay-passive = <0x64>;
			polling-delay = <0x3e8>;
			sustainable-power = <0x7d0>;
			thermal-sensors = <0xc9 0x00>;

			trips {

				trip-point@0 {
					temperature = <0x11170>;
					hysteresis = <0x3e8>;
					type = "passive";
				};

				trip-point@1 {
					temperature = <0x14c08>;
					hysteresis = <0x3e8>;
					type = "passive";
					linux,phandle = <0xca>;
					phandle = <0xca>;
				};

				gpu_crit {
					temperature = <0x1adb0>;
					hysteresis = <0x7d0>;
					type = "critical";
				};
			};

			cooling-maps {

				map0 {
					trip = <0xca>;
					contribution = <0x400>;
					cooling-device = <0xcb 0xffffffff 0xffffffff>;
				};
			};
		};

		chg-thmzone {
			polling-delay-passive = <0x00>;
			polling-delay = <0x00>;
			thermal-sensors = <0xcc 0x08>;
		};

		pa-thmzone {
			polling-delay-passive = <0x00>;
			polling-delay = <0x00>;
			thermal-sensors = <0xcd 0x09>;
		};

		board-thmzone {
			polling-delay-passive = <0x00>;
			polling-delay = <0x00>;
			thermal-sensors = <0xce 0x0a>;
		};
	};

	cooling-devices {

		cluster0-cooling {
			compatible = "sprd,cluster-cooling";
			#cooling-cells = <0x02>;
			sprd,efuse-block7 = <0x07>;
			sprd,efuse-block15 = <0x0f>;
			sprd,leak-core = <0x02 0x55 0x74d>;
			sprd,leak-cluster = <0x02 0x55 0x9dc>;
			sprd,core-temp-scale = <0x22 0xfffff448 0x23e38 0xffeb2428>;
			sprd,core-voltage-scale = <0xb2f 0xffffe14c 0x1d75 0xfffff698>;
			sprd,cluster-temp-scale = <0x1a 0xfffff830 0x1c138 0xfff0bdc0>;
			sprd,cluster-voltage-scale = <0x62e 0xffffef97 0xfdf 0xfffffae5>;
			sprd,efuse-switch = <0x00>;
			sprd,hotplug-period = <0x00>;
			sprd,min-cpufreq = <0xbb800>;
			sprd,min-cpunum = <0x04>;
			sprd,core-base = <0x10b>;
			sprd,cluster-base = <0x126>;
			sprd,dynamic-core = <0x352 0x300 0x384>;
			sprd,dynamic-cluster = <0x3d4 0x300 0x384>;
			linux,phandle = <0xc8>;
			phandle = <0xc8>;
		};
	};

	gpu-cooling-devices {

		gpu-cooling0 {
			compatible = "sprd,mali-power-model";
			#cooling-cells = <0x02>;
			sprd,efuse-block7 = <0x07>;
			sprd,efuse-block15 = <0x0f>;
			sprd,leak-core = <0x02 0x55 0x74d>;
			sprd,leak-cluster = <0x02 0x55 0x9dc>;
			sprd,temp-scale = <0x190 0x64 0x186a0 0x69e560>;
			sprd,voltage-scale = <0xc3 0xfffffe9a 0x157 0x5b>;
			sprd,hotplug-period = <0x00>;
			sprd,core-base = <0x2cc>;
			sprd,cluster-base = <0x00>;
			sprd,dynamic-core = <0x240e 0x300 0x41a>;
			sprd,dynamic-cluster = <0x00 0x00 0x00>;
			linux,phandle = <0xcb>;
			phandle = <0xcb>;
		};
	};

	chg-tsensor@8 {
		compatible = "sprd,board-thermal";
		#thermal-sensor-cells = <0x01>;
		io-channels = <0xb8 0x09>;
		io-channel-names = "adc_temp";
		temp-tab-size = <0x0f>;
		temp-tab-val = <0x46b 0x456 0x432 0x3d7 0x346 0x28e 0x19d 0x13c 0xee 0xb2 0x85 0x64 0x4b 0x39 0x2b>;
		temp-tab-temp = <0x25b 0x2be 0x325 0x3b8 0x44d 0x4e0 0x5a9 0x60d 0x671 0x6d5 0x739 0x79d 0x801 0x865 0x8c9>;
		status = "disabled";
		linux,phandle = <0xcc>;
		phandle = <0xcc>;
	};

	pa-tsensor@9 {
		compatible = "sprd,board-thermal";
		#thermal-sensor-cells = <0x01>;
		io-channels = <0xb8 0x05>;
		io-channel-names = "adc_temp";
		temp-tab-size = <0x0f>;
		temp-tab-val = <0x46b 0x456 0x432 0x3d7 0x346 0x28e 0x19d 0x13c 0xee 0xb2 0x85 0x64 0x4b 0x39 0x2b>;
		temp-tab-temp = <0x25b 0x2be 0x325 0x3b8 0x44d 0x4e0 0x5a9 0x60d 0x671 0x6d5 0x739 0x79d 0x801 0x865 0x8c9>;
		status = "disabled";
		linux,phandle = <0xcd>;
		phandle = <0xcd>;
	};

	bd-tsensor@10 {
		compatible = "sprd,board-thermal";
		#thermal-sensor-cells = <0x01>;
		io-channels = <0xb8 0x03>;
		io-channel-names = "adc_temp";
		temp-tab-size = <0x0f>;
		temp-tab-val = <0x46b 0x456 0x432 0x3d7 0x346 0x28e 0x19d 0x13c 0xee 0xb2 0x85 0x64 0x4b 0x39 0x2b>;
		temp-tab-temp = <0x25b 0x2be 0x325 0x3b8 0x44d 0x4e0 0x5a9 0x60d 0x671 0x6d5 0x739 0x79d 0x801 0x865 0x8c9>;
		linux,phandle = <0xce>;
		phandle = <0xce>;
	};

	reserved-memory {
		#address-cells = <0x02>;
		#size-cells = <0x02>;
		ranges;

		mpu0-dump@877ff000 {
			reg = <0x00 0x877ff000 0x00 0x1000>;
		};

		sipc-mem@87800000 {
			reg = <0x00 0x87800000 0x00 0x3d0000>;
			linux,phandle = <0xd9>;
			phandle = <0xd9>;
		};

		wcn-mem@88000000 {
			reg = <0x00 0x88000000 0x00 0x300000>;
			linux,phandle = <0xb4>;
			phandle = <0xb4>;
		};

		gnss-mem@88300000 {
			reg = <0x00 0x88300000 0x00 0x15a800>;
			linux,phandle = <0xb7>;
			phandle = <0xb7>;
		};

		pstore@8845a800 {
			reg = <0x00 0x8845a800 0x00 0x40000>;
			linux,phandle = <0xcf>;
			phandle = <0xcf>;
		};

		cp-modem@89600000 {
			reg = <0x00 0x89600000 0x00 0x4240000>;
			sprd,cpdbg-size = <0x280000>;
			linux,phandle = <0xd8>;
			phandle = <0xd8>;
		};

		audio_dma@8d840000 {
			reg = <0x00 0x8d840000 0x00 0x80000>;
			linux,phandle = <0x9e>;
			phandle = <0x9e>;
		};

		sml-mem@94000000 {
			reg = <0x00 0x94000000 0x00 0x20000>;
		};

		tos-mem@94020000 {
			reg = <0x00 0x94020000 0x00 0x1fe0000>;
		};

		sh-mem@96000000 {
			reg = <0x00 0x96000000 0x00 0x100000>;
		};

		iq-mem@98100000 {
			compatible = "sprd,iq-mem";
			reg = <0x00 0x98100000 0x00 0x4000000>;
			linux,phandle = <0xd6>;
			phandle = <0xd6>;
		};

		camera@bdf64000 {
			reg = <0x00 0xbdf64000 0x00 0x500000>;
			linux,phandle = <0xd2>;
			phandle = <0xd2>;
		};

		fb@be464000 {
			reg = <0x00 0xbe464000 0x00 0xe10000>;
			linux,phandle = <0xd1>;
			phandle = <0xd1>;
		};

		overlaybuffer@bf274000 {
			reg = <0x00 0xbf274000 0x00 0xa8c000>;
			linux,phandle = <0xd0>;
			phandle = <0xd0>;
		};
	};

	ramoops {
		compatible = "ramoops";
		memory-region = <0xcf>;
		record-size = <0x00 0x8000>;
		console-size = <0x00 0x8000>;
		pmsg-size = <0x00 0x8000>;
	};

	ion {
		compatible = "sprd,ion";
		#address-cells = <0x01>;
		#size-cells = <0x00>;
		phys-offset = <0x80000000>;

		heap@0 {
			reg = <0x00>;
			label = "system";
			type = <0x00>;
		};

		heap@2 {
			reg = <0x02>;
			label = "carveout_overlay";
			type = <0x02>;
			memory-region = <0xd0>;
		};

		heap@3 {
			reg = <0x03>;
			label = "carveout_fb";
			type = <0x02>;
			memory-region = <0xd1>;
		};

		heap@4 {
			reg = <0x04>;
			label = "carveout_camera";
			type = <0x02>;
			memory-region = <0xd2>;
		};
	};

	sprd-adf {
		compatible = "sprd-adf";
		status = "okay";
		sprd,display-mode = <0x03>;
		sprd,dispc = <0xd3>;
	};

	sprd_backlight {
		compatible = "pwm-backlight";
		pwms = <0xd4 0x00 0x4e20>;
		pwm-names = "backlight";
		brightness_max = <0x100>;
		brightness-levels = <0x06 0x06 0x06 0x06 0x06 0x06 0x06 0x06 0x06 0x06 0x06 0x07 0x08 0x09 0x0a 0x0b 0x0c 0x0d 0x0e 0x0f 0x10 0x11 0x12 0x13 0x14 0x15 0x16 0x17 0x18 0x19 0x1a 0x1b 0x1c 0x1d 0x1e 0x1f 0x20 0x21 0x22 0x23 0x24 0x25 0x26 0x27 0x28 0x29 0x2a 0x2b 0x2c 0x2d 0x2e 0x2f 0x30 0x31 0x32 0x33 0x34 0x35 0x36 0x37 0x38 0x39 0x3a 0x3b 0x3c 0x3d 0x3e 0x3f 0x40 0x41 0x42 0x43 0x44 0x45 0x46 0x47 0x48 0x49 0x4a 0x4b 0x4c 0x4d 0x4e 0x4f 0x50 0x51 0x52 0x53 0x54 0x55 0x56 0x57 0x58 0x59 0x5a 0x5b 0x5c 0x5d 0x5e 0x5f 0x60 0x61 0x62 0x63 0x64 0x65 0x66 0x67 0x68 0x69 0x6a 0x6b 0x6c 0x6d 0x6e 0x6f 0x70 0x71 0x72 0x73 0x74 0x75 0x76 0x77 0x78 0x79 0x7a 0x7b 0x7c 0x7d 0x7e 0x7f 0x80 0x81 0x82 0x83 0x84 0x85 0x86 0x87 0x88 0x89 0x8a 0x8b 0x8c 0x8d 0x8e 0x8f 0x90 0x91 0x92 0x93 0x94 0x95 0x96 0x97 0x98 0x99 0x9a 0x9b 0x9c 0x9d 0x9e 0x9f 0xa0 0xa1 0xa2 0xa3 0xa4 0xa5 0xa6 0xa7 0xa8 0xa9 0xaa 0xab 0xac 0xad 0xae 0xaf 0xb0 0xb1 0xb2 0xb3 0xb4 0xb5 0xb6 0xb7 0xb8 0xb9 0xba 0xbb 0xbc 0xbd 0xbe 0xbf 0xc0 0xc1 0xc2 0xc3 0xc4 0xc5 0xc6 0xc7 0xc8 0xc9 0xca 0xcb 0xcc 0xcd 0xce 0xcf 0xd0 0xd1 0xd2 0xd3 0xd4 0xd5 0xd6 0xd7 0xd8 0xd9 0xda 0xdb 0xdc 0xdd 0xde 0xdf 0xe0 0xe1 0xe2 0xe3 0xe4 0xe5 0xe6 0xe7 0xe8 0xe9 0xea 0xeb 0xec 0xed 0xee 0xef 0xf0 0xf1 0xf2 0xf3 0xf4 0xf5 0xf6 0xf7 0xf8 0xf9 0xfa 0xfb>;
		default-brightness-level = <0x64>;
	};

	memory@80000000 {
		device_type = "memory";
		reg = <0x00 0x80000000 0x00 0x80000000>;
		linux,phandle = <0xd7>;
		phandle = <0xd7>;
	};

	chosen {
		stdout-path = "/soc/ap-apb/serial@70100000";
		bootargs = "earlycon=sprd_serial,0x70100000,115200n8 console=ttyS1,115200n8 loglevel=8 init=/init root=/dev/ram0 rw androidboot.hardware=sp9832e_1h10";
	};

	interrupt-controller {
		compatible = "android,CustomIPI";
		#interrupt-cells = <0x01>;
		interrupt-controller;
		linux,phandle = <0xd5>;
		phandle = <0xd5>;
	};

	trusty {
		compatible = "android,trusty-smc-v1";

		irq {
			compatible = "android,trusty-irq-v1";
			interrupt-templates = <0xd5 0x00 0x01 0x01 0x01 0x00 0x01 0x01 0x00 0x00>;
			interrupt-ranges = <0x00 0x0f 0x00 0x10 0x1f 0x01 0x20 0xdf 0x02>;
		};

		virtio {
			compatible = "android,trusty-virtio-v1";
		};

		log {
			compatible = "android,trusty-log-v1";
		};
	};

	sprd-iq {
		compatible = "sprd,iq";
		sprd,region = <0xd6>;
		sprd,mapping-offs = <0x00>;
	};

	sprd-sysdump {
		memory-region = <0xd7>;
		memory-region-re = <0xd8 0xb4 0xd9 0xb7>;
	};

	sprd_map_user {
		compatible = "sprd,sprd_map_user";
	};

	sprd-wlan {
		compatible = "sprd,sp9832e";
	};

	gpio-keys {
		compatible = "gpio-keys";
		input-name = "sprd-gpio-keys";
		status = "ok";

		key-volumndown {
			label = "Volume Down Key";
			linux,code = <0x72>;
			gpios = <0x19 0x0a 0x00>;
			debounce-interval = <0x02>;
			gpio-key,wakeup;
			gpio-key,level-trigger;
		};

		key-volumeup {
			label = "Volume Up Key";
			linux,code = <0x73>;
			gpios = <0xda 0x02 0x01>;
			debounce-interval = <0x02>;
			gpio-key,wakeup;
			gpio-key,level-trigger;
		};

		key-power {
			label = "Power Key";
			linux,code = <0x74>;
			gpios = <0x19 0x01 0x01>;
			gpio-key,wakeup;
			gpio-key,level-trigger;
		};
	};

	flash-gpios {
		compatible = "sprd,flash-gpio";
	};

	sunwave-fp {
		compatible = "sunwave,fingerprint";
		sunwave,reset-gpio = <0x10 0x83 0x00>;
		sunwave,irq-gpio = <0x29 0x0d 0x00>;
	};

	fingerprint {
		compatible = "fpsensor,fingerprint";
		fpreset-gpios = <0x10 0x83 0x00>;
		fpint-gpios = <0x29 0x0d 0x00>;
	};

	ma-fingerprint {
		compatible = "microarray,fingerprint";
		maint-gpios = <0x29 0x0d 0x00>;
	};

	fingerprint_blestech {
		compatible = "sprd,betterlife-fp";
		reset-gpio = <0x10 0x83 0x00>;
		int_gpio = <0x29 0x0d 0x00>;
	};

	scene-frequency {
		compatible = "sprd,dfs";
		sprd-scene = "lcdon\0lcdoff\0camlow\0camhigh";
		sprd-freq = <0x100 0x100 0x180 0x29b>;
	};
};
